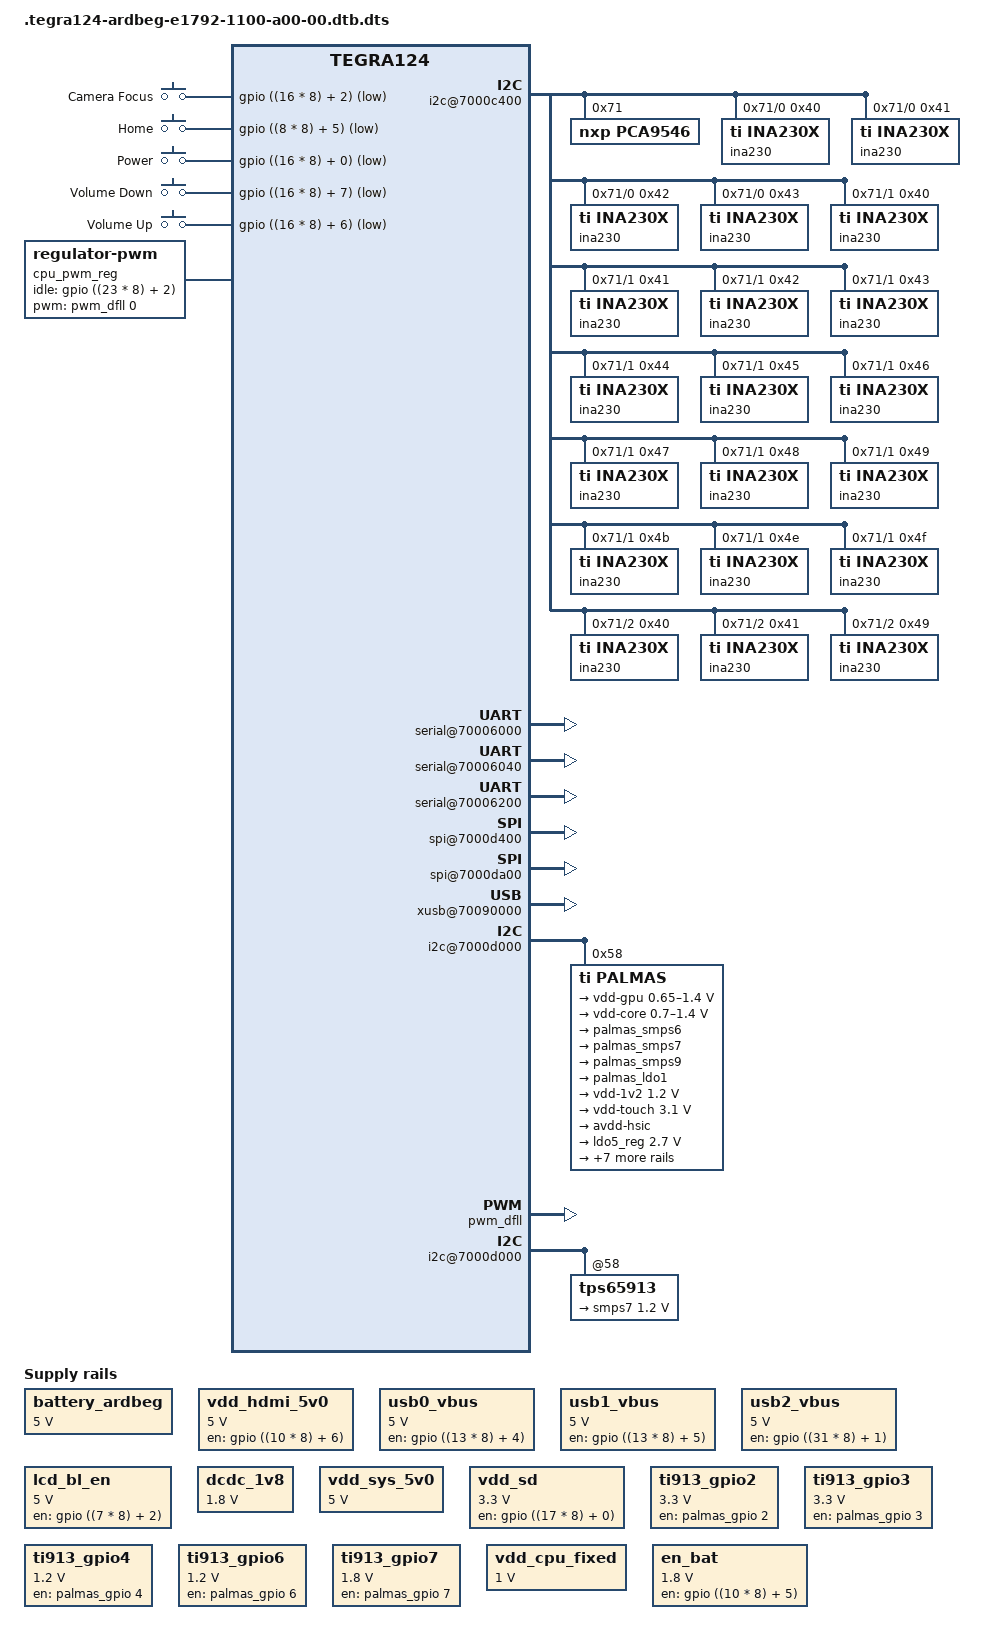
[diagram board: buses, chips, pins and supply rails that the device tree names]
# 1 "arch/arm/boot/dts/tegra124-ardbeg-e1792-1100-a00-00.dts"
# 1 "<built-in>"
# 1 "<command-line>"
# 1 "arch/arm/boot/dts/tegra124-ardbeg-e1792-1100-a00-00.dts"
/dts-v1/;

# 1 "arch/arm/boot/dts/tegra124-ardbeg-e1780-1000-a03-common.dtsi" 1




# 1 "arch/arm/boot/dts/tegra124.dtsi" 1
# 1 "/media/madman/Extended_Linux/21.8_l4t_build/kernel/arch/arm/boot/dts/include/dt-bindings/gpio/tegra-gpio.h" 1
# 13 "/media/madman/Extended_Linux/21.8_l4t_build/kernel/arch/arm/boot/dts/include/dt-bindings/gpio/tegra-gpio.h"
# 1 "/media/madman/Extended_Linux/21.8_l4t_build/kernel/arch/arm/boot/dts/include/dt-bindings/gpio/gpio.h" 1
# 14 "/media/madman/Extended_Linux/21.8_l4t_build/kernel/arch/arm/boot/dts/include/dt-bindings/gpio/tegra-gpio.h" 2
# 2 "arch/arm/boot/dts/tegra124.dtsi" 2
# 1 "/media/madman/Extended_Linux/21.8_l4t_build/kernel/arch/arm/boot/dts/include/dt-bindings/input/input.h" 1
# 3 "arch/arm/boot/dts/tegra124.dtsi" 2
# 1 "/media/madman/Extended_Linux/21.8_l4t_build/kernel/arch/arm/boot/dts/include/dt-bindings/interrupt-controller/arm-gic.h" 1







# 1 "/media/madman/Extended_Linux/21.8_l4t_build/kernel/arch/arm/boot/dts/include/dt-bindings/interrupt-controller/irq.h" 1
# 9 "/media/madman/Extended_Linux/21.8_l4t_build/kernel/arch/arm/boot/dts/include/dt-bindings/interrupt-controller/arm-gic.h" 2
# 4 "arch/arm/boot/dts/tegra124.dtsi" 2
# 1 "/media/madman/Extended_Linux/21.8_l4t_build/kernel/arch/arm/boot/dts/include/dt-bindings/ata/ahci-tegra.h" 1
# 5 "arch/arm/boot/dts/tegra124.dtsi" 2

/include/ "tegra124-soc.dtsi"

/ {
 compatible = "nvidia,tegra124";
 interrupt-parent = <&intc>;
 #address-cells = <2>;
 #size-cells = <2>;

 mc {
  compatible = "nvidia,tegra-mc";

  reg-ranges = <9>;
  reg = <0x0 0x70019000 0x0 0x00c>,
        <0x0 0x70019050 0x0 0x19c>,
        <0x0 0x70019200 0x0 0x024>,
        <0x0 0x7001929c 0x0 0x1b8>,
        <0x0 0x70019464 0x0 0x198>,
        <0x0 0x70019604 0x0 0x3b0>,
        <0x0 0x700199bc 0x0 0x020>,
        <0x0 0x700199f8 0x0 0x08c>,
        <0x0 0x70019ab4 0x0 0x54c>;

  interrupts = <0 77 0x4>;
  int_count = <8>;
  int_mask = <0x13D40>;

  channels = <1>;
 };

 intc: interrupt-controller@50041000 {
  compatible = "arm,cortex-a15-gic";
  interrupt-controller;
  #interrupt-cells = <3>;
  reg = <0x0 0x50041000 0x0 0x1000>,
        <0x0 0x50042000 0x0 0x0100>;
 };

 lic: interrupt-controller@60004000 {
  compatible = "nvidia,tegra-gic";
  interrupt-controller;
  reg = <0x0 0x60004000 0x0 0x40>,
        <0x0 0x60004100 0x0 0x40>,
        <0x0 0x60004200 0x0 0x40>,
        <0x0 0x60004300 0x0 0x40>,
        <0x0 0x60004400 0x0 0x40>;
        };

 cpus {
  #address-cells = <1>;
  #size-cells = <0>;

  cpu@0 {
   device_type = "cpu";
   compatible = "arm,cortex-a15";
   reg = <0>;
  };

  cpu@1 {
   device_type = "cpu";
   compatible = "arm,cortex-a15";
   reg = <1>;
  };

  cpu@2 {
   device_type = "cpu";
   compatible = "arm,cortex-a15";
   reg = <2>;
  };

  cpu@3 {
   device_type = "cpu";
   compatible = "arm,cortex-a15";
   reg = <3>;
  };
 };

 timer {
  compatible = "arm,armv7-timer";
  interrupts = <1 13 0xf04
         1 14 0xf04>;
 };

 dfll@70110000 {
   compatible = "nvidia,tegra124-dfll";
   reg = <0x0 0x70110000 0x0 0x400>;
   out-clock-name="dfll_cpu";
   status = "disabled";
 };
};
# 6 "arch/arm/boot/dts/tegra124-ardbeg-e1780-1000-a03-common.dtsi" 2
# 1 "arch/arm/boot/dts/tegra124-platforms/tegra124-ardbeg-powermon-e1780-1000-a01.dtsi" 1
# 18 "arch/arm/boot/dts/tegra124-platforms/tegra124-ardbeg-powermon-e1780-1000-a01.dtsi"
/ {
 i2c@7000c400 {
  pca9546@71 {
   compatible = "nxp,pca9546";
   reg = <0x71>;
   #address-cells = <1>;
   #size-cells = <0>;
   pca9546_i2c0: i2c@0 {
    reg = <0>;
    i2c-mux,deselect-on-exit;
    #address-cells = <1>;
    #size-cells = <0>;

    ina230@40{
     compatible = "ti,ina230x";
     reg = <0x40>;
     ti,rail-name = "__VDD_BAT";
     ti,continuous-config = <0x0407>;
     ti,trigger-config = <0x0403>;
     ti,resistor = <10>;
     ti,calibration-data = <0x1366>;
     ti,power-lsb = <2577>;
     ti,divisor = <25>;
     ti,precision-multiplier = <1000>;
    };

    ina230@41{
     compatible = "ti,ina230x";
     reg = <0x41>;
     ti,rail-name = "__VDD_SYS_BUCKCPU";
     ti,continuous-config = <0x0407>;
     ti,trigger-config = <0x0403>;
     ti,resistor = <10>;
     ti,calibration-data = <0x1AC5>;
     ti,power-lsb = <1867>;
     ti,divisor = <25>;
     ti,precision-multiplier = <1000>;
    };

    ina230@42{
     compatible = "ti,ina230x";
     reg = <0x42>;
     ti,rail-name = "__VDD_SYS_BUCKSOC";
     ti,continuous-config = <0x0407>;
     ti,trigger-config = <0x0403>;
     ti,resistor = <20>;
     ti,calibration-data = <0x2802>;
     ti,power-lsb = <624>;
     ti,divisor = <25>;
     ti,precision-multiplier = <1000>;
    };

    ina230@43{
     compatible = "ti,ina230x";
     reg = <0x43>;
     ti,rail-name = "__VDD_SYS_BUCKGPU";
     ti,continuous-config = <0x0407>;
     ti,trigger-config = <0x0403>;
     ti,resistor = <10>;
     ti,calibration-data = <0x1F38>;
     ti,power-lsb = <1601>;
     ti,divisor = <25>;
     ti,precision-multiplier = <1000>;
    };
   };

   pca9546_i2c1: i2c@1 {
    reg = <1>;
    i2c-mux,deselect-on-exit;
    #address-cells = <1>;
    #size-cells = <0>;
    ina230@40{
     compatible = "ti,ina230x";
     reg = <0x40>;
     ti,rail-name = "VDD_SYS_BAT";
     ti,continuous-config = <0x0407>;
     ti,trigger-config = <0x0403>;
     ti,resistor = <10>;
     ti,calibration-data = <0x1366>;
     ti,power-lsb = <2577>;
     ti,divisor = <25>;
     ti,precision-multiplier = <1000>;
    };

    ina230@41{
     compatible = "ti,ina230x";
     reg = <0x41>;
     ti,rail-name = "VDD_RTC_LDO3";
     ti,continuous-config = <0x0407>;
     ti,trigger-config = <0x0403>;
     ti,resistor = <50>;
     ti,calibration-data = <0x7FFF>;
     ti,power-lsb = <78>;
     ti,divisor = <25>;
     ti,precision-multiplier = <1000>;
    };

    ina230@42{
     compatible = "ti,ina230x";
     reg = <0x42>;
     ti,rail-name = "VDD_SYS_BUCKSOC";
     ti,continuous-config = <0x0407>;
     ti,trigger-config = <0x0403>;
     ti,resistor = <30>;
     ti,calibration-data = <0x1AAC>;
     ti,power-lsb = <624>;
     ti,divisor = <25>;
     ti,precision-multiplier = <1000>;
    };

    ina230@43{
     compatible = "ti,ina230x";
     reg = <0x43>;
     ti,rail-name = "VDD_SOC_SD1";
     ti,continuous-config = <0x0407>;
     ti,trigger-config = <0x0403>;
     ti,resistor = <1>;
     ti,calibration-data = <0x7FFF>;
     ti,power-lsb = <3906>;
     ti,divisor = <25>;
     ti,precision-multiplier = <1000>;
    };

    ina230@44{
     compatible = "ti,ina230x";
     reg = <0x44>;
     ti,rail-name = "VDD_SYS_BUCKCPU";
     ti,continuous-config = <0x0407>;
     ti,trigger-config = <0x0403>;
     ti,resistor = <10>;
     ti,calibration-data = <0x1AC5>;
     ti,power-lsb = <1867>;
     ti,divisor = <25>;
     ti,precision-multiplier = <1000>;
    };

    ina230@45{
     compatible = "ti,ina230x";
     reg = <0x45>;
     ti,rail-name = "VDD_CPU_BUCKCPU";
     ti,continuous-config = <0x0407>;
     ti,trigger-config = <0x0403>;
     ti,resistor = <1>;
     ti,calibration-data = <0x2ECF>;
     ti,power-lsb = <10681>;
     ti,divisor = <25>;
     ti,precision-multiplier = <1000>;
    };

    ina230@46{
     compatible = "ti,ina230x";
     reg = <0x46>;
     ti,rail-name = "VDD_1V8_SD5";
     ti,continuous-config = <0x0407>;
     ti,trigger-config = <0x0403>;
     ti,resistor = <10>;
     ti,calibration-data = <0x45F0>;
     ti,power-lsb = <714>;
     ti,divisor = <25>;
     ti,precision-multiplier = <1000>;
    };

    ina230@47{
     compatible = "ti,ina230x";
     reg = <0x47>;
     ti,rail-name = "VDD_3V3A_LDO1_6";
     ti,continuous-config = <0x0407>;
     ti,trigger-config = <0x0403>;
     ti,resistor = <200>;
     ti,calibration-data = <0x3A83>;
     ti,power-lsb = <42>;
     ti,divisor = <25>;
     ti,precision-multiplier = <1000>;
    };

    ina230@48{
     compatible = "ti,ina230x";
     reg = <0x48>;
     ti,rail-name = "VDD_DIS_3V3_LCD";
     ti,continuous-config = <0x0407>;
     ti,trigger-config = <0x0403>;
     ti,resistor = <10>;
     ti,calibration-data = <0x7FFF>;
     ti,power-lsb = <390>;
     ti,divisor = <25>;
     ti,precision-multiplier = <1000>;
    };

    ina230@49{
     compatible = "ti,ina230x";
     reg = <0x49>;
     ti,rail-name = "VDD_1V35_SD2";
     ti,continuous-config = <0x0407>;
     ti,trigger-config = <0x0403>;
     ti,resistor = <1>;
     ti,calibration-data = <0x7FFF>;
     ti,power-lsb = <3906>;
     ti,divisor = <25>;
     ti,precision-multiplier = <1000>;
    };

    ina230@4b{
     compatible = "ti,ina230x";
     reg = <0x4b>;
     ti,rail-name = "VDD_SYS_BUCKGPU";
     ti,continuous-config = <0x0407>;
     ti,trigger-config = <0x0403>;
     ti,resistor = <10>;
     ti,calibration-data = <0x1F38>;
     ti,power-lsb = <1601>;
     ti,divisor = <25>;
     ti,precision-multiplier = <1000>;
    };

    ina230@4e{
     compatible = "ti,ina230x";
     reg = <0x4e>;
     ti,rail-name = "VDD_LCD_1V8B_DIS";
     ti,continuous-config = <0x0407>;
     ti,trigger-config = <0x0403>;
     ti,resistor = <100>;
     ti,calibration-data = <0x7FFF>;
     ti,power-lsb = <39>;
     ti,divisor = <25>;
     ti,precision-multiplier = <1000>;
    };

    ina230@4f{
     compatible = "ti,ina230x";
     reg = <0x4f>;
     ti,rail-name = "VDD_1V05_LDO0";
     ti,continuous-config = <0x0407>;
     ti,trigger-config = <0x0403>;
     ti,resistor = <30>;
     ti,calibration-data = <0x7FFF>;
     ti,power-lsb = <130>;
     ti,divisor = <25>;
     ti,precision-multiplier = <1000>;
    };
   };

   pca9546_i2c2: i2c@2 {
    reg = <2>;
    i2c-mux,deselect-on-exit;
    #address-cells = <1>;
    #size-cells = <0>;
    ina230@40{
     compatible = "ti,ina230x";
     reg = <0x40>;
     ti,rail-name = "VDD_1V05_SD4";
     ti,continuous-config = <0x0407>;
     ti,trigger-config = <0x0403>;
     ti,resistor = <10>;
     ti,calibration-data = <0x7FFF>;
     ti,power-lsb = <390>;
     ti,divisor = <25>;
     ti,precision-multiplier = <1000>;
    };

    ina230@41{
     compatible = "ti,ina230x";
     reg = <0x41>;
     ti,rail-name = "VDD_1V8A_LDO2_5_7";
     ti,continuous-config = <0x0407>;
     ti,trigger-config = <0x0403>;
     ti,resistor = <20>;
     ti,calibration-data = <0x5A04>;
     ti,power-lsb = <277>;
     ti,divisor = <25>;
     ti,precision-multiplier = <1000>;
    };

    ina230@49{
     compatible = "ti,ina230x";
     reg = <0x49>;
     ti,rail-name = "VDD_SYS_BL";
     ti,continuous-config = <0x0407>;
     ti,trigger-config = <0x0403>;
     ti,resistor = <50>;
     ti,calibration-data = <0x2468>;
     ti,power-lsb = <274>;
     ti,divisor = <25>;
     ti,precision-multiplier = <1000>;
    };
   };

   pca9546_i2c3: i2c@3 {
    reg = <3>;
    i2c-mux,deselect-on-exit;
    #address-cells = <1>;
    #size-cells = <0>;
   };
  };
 };
};
# 7 "arch/arm/boot/dts/tegra124-ardbeg-e1780-1000-a03-common.dtsi" 2
# 1 "arch/arm/boot/dts/tegra124-platforms/tegra124-tn8-gpio-e1780-1100-a02.dtsi" 1
# 21 "arch/arm/boot/dts/tegra124-platforms/tegra124-tn8-gpio-e1780-1100-a02.dtsi"
/ {
 gpio: gpio@6000d000 {
  gpio-init-names = "default";
  gpio-init-0 = <&gpio_default>;

  gpio_default: default {
   gpio-input = < ((2 * 8) + 7)
     ((6 * 8) + 2)
     ((6 * 8) + 3)
     ((7 * 8) + 4)
     ((8 * 8) + 5)
     ((8 * 8) + 6)
     ((9 * 8) + 0)
     ((10 * 8) + 0)
     ((10 * 8) + 2)
     ((10 * 8) + 3)
     ((13 * 8) + 7)
     ((14 * 8) + 0)
     ((14 * 8) + 2)
     ((14 * 8) + 3)
     ((14 * 8) + 5)
     ((14 * 8) + 7)
     ((16 * 8) + 0)
     ((16 * 8) + 1)
     ((16 * 8) + 2)
     ((16 * 8) + 5)
     ((16 * 8) + 6)
     ((16 * 8) + 7)
     ((17 * 8) + 4)
     ((18 * 8) + 0)
     ((18 * 8) + 1)
     ((20 * 8) + 1)
     ((20 * 8) + 2)
     ((20 * 8) + 5)
     ((20 * 8) + 6)
     ((21 * 8) + 0)
     ((21 * 8) + 1)
     ((21 * 8) + 3)
     ((22 * 8) + 2)
     ((22 * 8) + 3)
     ((23 * 8) + 3)
     ((23 * 8) + 5)
     ((23 * 8) + 6)
     ((28 * 8) + 1)
     ((28 * 8) + 2)>;
   gpio-output-low = <((6 * 8) + 0)
     ((6 * 8) + 1)
     ((7 * 8) + 3)
     ((7 * 8) + 5)
     ((8 * 8) + 0)
     ((8 * 8) + 2)
     ((8 * 8) + 4)
     ((10 * 8) + 1)
     ((10 * 8) + 5)
     ((10 * 8) + 6)
     ((14 * 8) + 6)
     ((17 * 8) + 0)
     ((17 * 8) + 1)
     ((17 * 8) + 2)
     ((17 * 8) + 5)
     ((18 * 8) + 3)
     ((18 * 8) + 4)
     ((18 * 8) + 6)
     ((20 * 8) + 0)
     ((20 * 8) + 3)
     ((20 * 8) + 4)
     ((23 * 8) + 1)
     ((23 * 8) + 4)
     ((23 * 8) + 7)
     ((27 * 8) + 3)
     ((27 * 8) + 5)
     ((27 * 8) + 6)
     ((27 * 8) + 7)
     ((28 * 8) + 5)
     ((30 * 8) + 1)>;
   gpio-output-high = <((7 * 8) + 2)
     ((10 * 8) + 4)
     ((18 * 8) + 5)
     ((23 * 8) + 2)>;
  };
 };
};
# 8 "arch/arm/boot/dts/tegra124-ardbeg-e1780-1000-a03-common.dtsi" 2
# 1 "arch/arm/boot/dts/tegra124-platforms/tegra124-tn8-pinmux-e1780-1100-a02.dtsi" 1
# 19 "arch/arm/boot/dts/tegra124-platforms/tegra124-tn8-pinmux-e1780-1100-a02.dtsi"
# 1 "/media/madman/Extended_Linux/21.8_l4t_build/kernel/arch/arm/boot/dts/include/dt-bindings/pinctrl/pinctrl-tegra.h" 1
# 20 "arch/arm/boot/dts/tegra124-platforms/tegra124-tn8-pinmux-e1780-1100-a02.dtsi" 2

/ {

 i2c@7000c000 {
                pinctrl-names = "hs_mode";
                pinctrl-0 = <&gen1_i2c_hs_drive>;
        };

 i2c@7000c400 {
                pinctrl-names = "hs_mode";
                pinctrl-0 = <&gen2_i2c_hs_drive>;
        };

 i2c@7000c500 {
                pinctrl-names = "hs_mode";
                pinctrl-0 = <&cam_i2c_hs_drive>;
        };

 i2c@7000c700 {
                pinctrl-names = "hs_mode";
                pinctrl-0 = <&ddc_i2c_hs_drive>;
        };

 i2c@7000d000 {
                pinctrl-names = "hs_mode";
                pinctrl-0 = <&pwr_i2c_hs_drive>;
        };

 pinmux: pinmux {
  pinctrl-names = "default", "drive", "unused", "gen1_i2c_hs", "gen2_i2c_hs", "cam_i2c_hs", "ddc_i2c_hs", "pwr_i2c_hs";
  pinctrl-0 = <&pinmux_default>;
  pinctrl-1 = <&drive_default>;
  pinctrl-2 = <&pinmux_unused_lowpower>;
  pinctrl-3 = <&gen1_i2c_hs_drive>;
  pinctrl-4 = <&gen2_i2c_hs_drive>;
  pinctrl-5 = <&cam_i2c_hs_drive>;
  pinctrl-6 = <&ddc_i2c_hs_drive>;
  pinctrl-7 = <&pwr_i2c_hs_drive>;

  pinmux_default: common {
   dap_mclk1_pw4 {
    nvidia,pins = "dap_mclk1_pw4";
    nvidia,function = "extperiph1";
    nvidia,enable-input = <0>;
    nvidia,pull = <0>;
    nvidia,tristate = <0>;
   };

   dap1_din_pn1 {
    nvidia,pins = "dap1_din_pn1";
    nvidia,function = "i2s0";
    nvidia,enable-input = <1>;
    nvidia,pull = <0>;
    nvidia,tristate = <1>;
   };

   dap1_dout_pn2 {
    nvidia,pins = "dap1_dout_pn2";
    nvidia,function = "i2s0";
    nvidia,enable-input = <0>;
    nvidia,pull = <0>;
    nvidia,tristate = <1>;
   };

   dap1_fs_pn0 {
    nvidia,pins = "dap1_fs_pn0";
    nvidia,function = "i2s0";
    nvidia,enable-input = <1>;
    nvidia,pull = <0>;
    nvidia,tristate = <1>;
   };

   dap1_sclk_pn3 {
    nvidia,pins = "dap1_sclk_pn3";
    nvidia,function = "i2s0";
    nvidia,enable-input = <1>;
    nvidia,pull = <0>;
    nvidia,tristate = <1>;
   };

   dap2_din_pa4 {
    nvidia,pins = "dap2_din_pa4";
    nvidia,function = "i2s1";
    nvidia,enable-input = <1>;
    nvidia,pull = <0>;
    nvidia,tristate = <1>;
   };

   dap2_dout_pa5 {
    nvidia,pins = "dap2_dout_pa5";
    nvidia,function = "i2s1";
    nvidia,enable-input = <0>;
    nvidia,pull = <0>;
    nvidia,tristate = <1>;
   };

   dap2_fs_pa2 {
    nvidia,pins = "dap2_fs_pa2";
    nvidia,function = "i2s1";
    nvidia,enable-input = <1>;
    nvidia,pull = <0>;
    nvidia,tristate = <1>;
   };

   dap2_sclk_pa3 {
    nvidia,pins = "dap2_sclk_pa3";
    nvidia,function = "i2s1";
    nvidia,enable-input = <1>;
    nvidia,pull = <0>;
    nvidia,tristate = <1>;
   };

   dvfs_pwm_px0 {
    nvidia,pins = "dvfs_pwm_px0";
    nvidia,function = "cldvfs";
    nvidia,enable-input = <0>;
    nvidia,pull = <0>;
    nvidia,tristate = <1>;
   };

   dvfs_clk_px2 {
    nvidia,pins = "dvfs_clk_px2";
    nvidia,function = "cldvfs";
    nvidia,enable-input = <0>;
    nvidia,pull = <0>;
    nvidia,tristate = <0>;
   };

   ulpi_clk_py0 {
    nvidia,pins = "ulpi_clk_py0";
    nvidia,function = "spi1";
    nvidia,enable-input = <1>;
    nvidia,pull = <2>;
    nvidia,tristate = <0>;
   };

   ulpi_dir_py1 {
    nvidia,pins = "ulpi_dir_py1";
    nvidia,function = "spi1";
    nvidia,enable-input = <1>;
    nvidia,pull = <2>;
    nvidia,tristate = <0>;
   };

   ulpi_nxt_py2 {
    nvidia,pins = "ulpi_nxt_py2";
    nvidia,function = "spi1";
    nvidia,enable-input = <1>;
    nvidia,pull = <2>;
    nvidia,tristate = <0>;
   };

   ulpi_stp_py3 {
    nvidia,pins = "ulpi_stp_py3";
    nvidia,function = "spi1";
    nvidia,enable-input = <1>;
    nvidia,pull = <2>;
    nvidia,tristate = <0>;
   };

   cam_i2c_scl_pbb1 {
    nvidia,pins = "cam_i2c_scl_pbb1";
    nvidia,function = "i2c3";
    nvidia,enable-input = <1>;
    nvidia,pull = <0>;
    nvidia,tristate = <0>;
    nvidia,lock = <0>;
    nvidia,open-drain = <1>;
   };

   cam_i2c_sda_pbb2 {
    nvidia,pins = "cam_i2c_sda_pbb2";
    nvidia,function = "i2c3";
    nvidia,enable-input = <1>;
    nvidia,pull = <0>;
    nvidia,tristate = <0>;
    nvidia,lock = <0>;
    nvidia,open-drain = <1>;
   };

   cam_mclk_pcc0 {
    nvidia,pins = "cam_mclk_pcc0";
    nvidia,function = "vi_alt3";
    nvidia,enable-input = <0>;
    nvidia,pull = <0>;
    nvidia,tristate = <0>;
   };

   pbb0 {
    nvidia,pins = "pbb0";
    nvidia,function = "vimclk2_alt";
    nvidia,enable-input = <0>;
    nvidia,pull = <0>;
    nvidia,tristate = <0>;
   };

   pbb4 {
    nvidia,pins = "pbb4";
    nvidia,function = "vgp4";
    nvidia,enable-input = <0>;
    nvidia,pull = <0>;
    nvidia,tristate = <0>;
   };

   gen2_i2c_scl_pt5 {
    nvidia,pins = "gen2_i2c_scl_pt5";
    nvidia,function = "i2c2";
    nvidia,enable-input = <1>;
    nvidia,pull = <0>;
    nvidia,tristate = <0>;
    nvidia,lock = <0>;
    nvidia,open-drain = <1>;
   };

   gen2_i2c_sda_pt6 {
    nvidia,pins = "gen2_i2c_sda_pt6";
    nvidia,function = "i2c2";
    nvidia,enable-input = <1>;
    nvidia,pull = <0>;
    nvidia,tristate = <0>;
    nvidia,lock = <0>;
    nvidia,open-drain = <1>;
   };

   pj7 {
    nvidia,pins = "pj7";
    nvidia,function = "uartd";
    nvidia,enable-input = <0>;
    nvidia,pull = <0>;
    nvidia,tristate = <0>;
   };

   pb0 {
    nvidia,pins = "pb0";
    nvidia,function = "uartd";
    nvidia,enable-input = <1>;
    nvidia,pull = <2>;
    nvidia,tristate = <0>;
   };

   pb1 {
    nvidia,pins = "pb1";
    nvidia,function = "uartd";
    nvidia,enable-input = <1>;
    nvidia,pull = <2>;
    nvidia,tristate = <0>;
   };

   pk7 {
    nvidia,pins = "pk7";
    nvidia,function = "uartd";
    nvidia,enable-input = <0>;
    nvidia,pull = <0>;
    nvidia,tristate = <0>;
   };

   pg4 {
    nvidia,pins = "pg4";
    nvidia,function = "spi4";
    nvidia,enable-input = <0>;
    nvidia,pull = <0>;
    nvidia,tristate = <0>;
   };

   pg5 {
    nvidia,pins = "pg5";
    nvidia,function = "spi4";
    nvidia,enable-input = <0>;
    nvidia,pull = <0>;
    nvidia,tristate = <0>;
   };

   pg6 {
    nvidia,pins = "pg6";
    nvidia,function = "spi4";
    nvidia,enable-input = <0>;
    nvidia,pull = <0>;
    nvidia,tristate = <0>;
   };

   pg7 {
    nvidia,pins = "pg7";
    nvidia,function = "spi4";
    nvidia,enable-input = <1>;
    nvidia,pull = <0>;
    nvidia,tristate = <0>;
   };

   pi3 {
    nvidia,pins = "pi3";
    nvidia,function = "spi4";
    nvidia,enable-input = <0>;
    nvidia,pull = <0>;
    nvidia,tristate = <0>;
   };

   ph0 {
    nvidia,pins = "ph0";
    nvidia,function = "dtv";
    nvidia,enable-input = <1>;
    nvidia,pull = <1>;
    nvidia,tristate = <1>;
   };

   ph1 {
    nvidia,pins = "ph1";
    nvidia,function = "pwm1";
    nvidia,enable-input = <0>;
    nvidia,pull = <0>;
    nvidia,tristate = <0>;
   };

   pk0 {
    nvidia,pins = "pk0";
    nvidia,function = "safe";
    nvidia,enable-input = <1>;
    nvidia,pull = <1>;
    nvidia,tristate = <0>;
   };

   pj2 {
    nvidia,pins = "pj2";
    nvidia,function = "soc";
    nvidia,enable-input = <1>;
    nvidia,pull = <2>;
    nvidia,tristate = <0>;
   };

   kb_row15_ps7 {
    nvidia,pins = "kb_row15_ps7";
    nvidia,function = "soc";
    nvidia,enable-input = <1>;
    nvidia,pull = <2>;
    nvidia,tristate = <0>;
   };

   clk_32k_out_pa0 {
    nvidia,pins = "clk_32k_out_pa0";
    nvidia,function = "soc";
    nvidia,enable-input = <1>;
    nvidia,pull = <2>;
    nvidia,tristate = <0>;
   };

   clk2_out_pw5 {
    nvidia,pins = "clk2_out_pw5";
    nvidia,function = "extperiph2";
    nvidia,enable-input = <0>;
    nvidia,pull = <0>;
    nvidia,tristate = <0>;
   };

   sdmmc1_clk_pz0 {
    nvidia,pins = "sdmmc1_clk_pz0";
    nvidia,function = "sdmmc1";
    nvidia,enable-input = <1>;
    nvidia,pull = <0>;
    nvidia,tristate = <0>;
   };

   sdmmc1_cmd_pz1 {
    nvidia,pins = "sdmmc1_cmd_pz1";
    nvidia,function = "sdmmc1";
    nvidia,enable-input = <1>;
    nvidia,pull = <2>;
    nvidia,tristate = <0>;
   };

   sdmmc1_dat0_py7 {
    nvidia,pins = "sdmmc1_dat0_py7";
    nvidia,function = "sdmmc1";
    nvidia,enable-input = <1>;
    nvidia,pull = <2>;
    nvidia,tristate = <0>;
   };

   sdmmc1_dat1_py6 {
    nvidia,pins = "sdmmc1_dat1_py6";
    nvidia,function = "sdmmc1";
    nvidia,enable-input = <1>;
    nvidia,pull = <2>;
    nvidia,tristate = <0>;
   };

   sdmmc1_dat2_py5 {
    nvidia,pins = "sdmmc1_dat2_py5";
    nvidia,function = "sdmmc1";
    nvidia,enable-input = <1>;
    nvidia,pull = <2>;
    nvidia,tristate = <0>;
   };

   sdmmc1_dat3_py4 {
    nvidia,pins = "sdmmc1_dat3_py4";
    nvidia,function = "sdmmc1";
    nvidia,enable-input = <1>;
    nvidia,pull = <2>;
    nvidia,tristate = <0>;
   };

   sdmmc3_clk_pa6 {
    nvidia,pins = "sdmmc3_clk_pa6";
    nvidia,function = "sdmmc3";
    nvidia,enable-input = <1>;
    nvidia,pull = <0>;
    nvidia,tristate = <0>;
   };

   sdmmc3_cmd_pa7 {
    nvidia,pins = "sdmmc3_cmd_pa7";
    nvidia,function = "sdmmc3";
    nvidia,enable-input = <1>;
    nvidia,pull = <2>;
    nvidia,tristate = <0>;
   };

   sdmmc3_dat0_pb7 {
    nvidia,pins = "sdmmc3_dat0_pb7";
    nvidia,function = "sdmmc3";
    nvidia,enable-input = <1>;
    nvidia,pull = <2>;
    nvidia,tristate = <0>;
   };

   sdmmc3_dat1_pb6 {
    nvidia,pins = "sdmmc3_dat1_pb6";
    nvidia,function = "sdmmc3";
    nvidia,enable-input = <1>;
    nvidia,pull = <2>;
    nvidia,tristate = <0>;
   };

   sdmmc3_dat2_pb5 {
    nvidia,pins = "sdmmc3_dat2_pb5";
    nvidia,function = "sdmmc3";
    nvidia,enable-input = <1>;
    nvidia,pull = <2>;
    nvidia,tristate = <0>;
   };

   sdmmc3_dat3_pb4 {
    nvidia,pins = "sdmmc3_dat3_pb4";
    nvidia,function = "sdmmc3";
    nvidia,enable-input = <1>;
    nvidia,pull = <2>;
    nvidia,tristate = <0>;
   };

   sdmmc3_clk_lb_out_pee4 {
    nvidia,pins = "sdmmc3_clk_lb_out_pee4";
    nvidia,function = "sdmmc3";
    nvidia,enable-input = <1>;
    nvidia,pull = <2>;
    nvidia,tristate = <0>;
   };

   sdmmc3_clk_lb_in_pee5 {
    nvidia,pins = "sdmmc3_clk_lb_in_pee5";
    nvidia,function = "sdmmc3";
    nvidia,enable-input = <1>;
    nvidia,pull = <2>;
    nvidia,tristate = <0>;
   };

   kb_col4_pq4 {
    nvidia,pins = "kb_col4_pq4";
    nvidia,function = "sdmmc3";
    nvidia,enable-input = <1>;
    nvidia,pull = <2>;
    nvidia,tristate = <0>;
   };

   sdmmc3_cd_n_pv2 {
    nvidia,pins = "sdmmc3_cd_n_pv2";
    nvidia,function = "sdmmc3";
    nvidia,enable-input = <1>;
    nvidia,pull = <2>;
    nvidia,tristate = <0>;
   };

   sdmmc4_clk_pcc4 {
    nvidia,pins = "sdmmc4_clk_pcc4";
    nvidia,function = "sdmmc4";
    nvidia,enable-input = <1>;
    nvidia,pull = <0>;
    nvidia,tristate = <0>;
   };

   sdmmc4_cmd_pt7 {
    nvidia,pins = "sdmmc4_cmd_pt7";
    nvidia,function = "sdmmc4";
    nvidia,enable-input = <1>;
    nvidia,pull = <2>;
    nvidia,tristate = <0>;
   };

   sdmmc4_dat0_paa0 {
    nvidia,pins = "sdmmc4_dat0_paa0";
    nvidia,function = "sdmmc4";
    nvidia,enable-input = <1>;
    nvidia,pull = <2>;
    nvidia,tristate = <0>;
   };

   sdmmc4_dat1_paa1 {
    nvidia,pins = "sdmmc4_dat1_paa1";
    nvidia,function = "sdmmc4";
    nvidia,enable-input = <1>;
    nvidia,pull = <2>;
    nvidia,tristate = <0>;
   };

   sdmmc4_dat2_paa2 {
    nvidia,pins = "sdmmc4_dat2_paa2";
    nvidia,function = "sdmmc4";
    nvidia,enable-input = <1>;
    nvidia,pull = <2>;
    nvidia,tristate = <0>;
   };

   sdmmc4_dat3_paa3 {
    nvidia,pins = "sdmmc4_dat3_paa3";
    nvidia,function = "sdmmc4";
    nvidia,enable-input = <1>;
    nvidia,pull = <2>;
    nvidia,tristate = <0>;
   };

   sdmmc4_dat4_paa4 {
    nvidia,pins = "sdmmc4_dat4_paa4";
    nvidia,function = "sdmmc4";
    nvidia,enable-input = <1>;
    nvidia,pull = <2>;
    nvidia,tristate = <0>;
   };

   sdmmc4_dat5_paa5 {
    nvidia,pins = "sdmmc4_dat5_paa5";
    nvidia,function = "sdmmc4";
    nvidia,enable-input = <1>;
    nvidia,pull = <2>;
    nvidia,tristate = <0>;
   };

   sdmmc4_dat6_paa6 {
    nvidia,pins = "sdmmc4_dat6_paa6";
    nvidia,function = "sdmmc4";
    nvidia,enable-input = <1>;
    nvidia,pull = <2>;
    nvidia,tristate = <0>;
   };

   sdmmc4_dat7_paa7 {
    nvidia,pins = "sdmmc4_dat7_paa7";
    nvidia,function = "sdmmc4";
    nvidia,enable-input = <1>;
    nvidia,pull = <2>;
    nvidia,tristate = <0>;
   };

   kb_row10_ps2 {
    nvidia,pins = "kb_row10_ps2";
    nvidia,function = "uarta";
    nvidia,enable-input = <1>;
    nvidia,pull = <2>;
    nvidia,tristate = <0>;
   };

   kb_row9_ps1 {
    nvidia,pins = "kb_row9_ps1";
    nvidia,function = "uarta";
    nvidia,enable-input = <0>;
    nvidia,pull = <0>;
    nvidia,tristate = <0>;
   };

   kb_row3_pr3 {
    nvidia,pins = "kb_row3_pr3";
    nvidia,function = "sys";
    nvidia,enable-input = <0>;
    nvidia,pull = <0>;
    nvidia,tristate = <0>;
   };

   kb_row6_pr6 {
    nvidia,pins = "kb_row6_pr6";
    nvidia,function = "displaya_alt";
    nvidia,enable-input = <1>;
    nvidia,pull = <0>;
    nvidia,tristate = <0>;
   };

   pwr_i2c_scl_pz6 {
    nvidia,pins = "pwr_i2c_scl_pz6";
    nvidia,function = "i2cpwr";
    nvidia,enable-input = <1>;
    nvidia,pull = <0>;
    nvidia,tristate = <0>;
    nvidia,open-drain = <1>;
   };

   pwr_i2c_sda_pz7 {
    nvidia,pins = "pwr_i2c_sda_pz7";
    nvidia,function = "i2cpwr";
    nvidia,enable-input = <1>;
    nvidia,pull = <0>;
    nvidia,tristate = <0>;
    nvidia,open-drain = <1>;
   };

   jtag_rtck {
    nvidia,pins = "jtag_rtck";
    nvidia,function = "rtck";
    nvidia,enable-input = <0>;
    nvidia,pull = <2>;
    nvidia,tristate = <0>;
   };

   clk_32k_in {
    nvidia,pins = "clk_32k_in";
    nvidia,function = "clk";
    nvidia,enable-input = <1>;
    nvidia,pull = <0>;
    nvidia,tristate = <0>;
   };

   core_pwr_req {
    nvidia,pins = "core_pwr_req";
    nvidia,function = "pwron";
    nvidia,enable-input = <0>;
    nvidia,pull = <0>;
    nvidia,tristate = <0>;
   };

   cpu_pwr_req {
    nvidia,pins = "cpu_pwr_req";
    nvidia,function = "cpu";
    nvidia,enable-input = <0>;
    nvidia,pull = <0>;
    nvidia,tristate = <0>;
   };

   pwr_int_n {
    nvidia,pins = "pwr_int_n";
    nvidia,function = "pmi";
    nvidia,enable-input = <1>;
    nvidia,pull = <2>;
    nvidia,tristate = <0>;
   };

   reset_out_n {
    nvidia,pins = "reset_out_n";
    nvidia,function = "reset_out_n";
    nvidia,enable-input = <0>;
    nvidia,pull = <0>;
    nvidia,tristate = <0>;
   };

   clk3_out_pee0 {
    nvidia,pins = "clk3_out_pee0";
    nvidia,function = "extperiph3";
    nvidia,enable-input = <0>;
    nvidia,pull = <0>;
    nvidia,tristate = <0>;
   };

   dp_hpd_pff0 {
    nvidia,pins = "dp_hpd_pff0";
    nvidia,function = "dp";
    nvidia,enable-input = <1>;
    nvidia,pull = <0>;
    nvidia,tristate = <0>;
   };

   dap4_din_pp5 {
    nvidia,pins = "dap4_din_pp5";
    nvidia,function = "i2s3";
    nvidia,enable-input = <1>;
    nvidia,pull = <0>;
    nvidia,tristate = <1>;
   };

   dap4_dout_pp6 {
    nvidia,pins = "dap4_dout_pp6";
    nvidia,function = "i2s3";
    nvidia,enable-input = <0>;
    nvidia,pull = <0>;
    nvidia,tristate = <1>;
   };

   dap4_fs_pp4 {
    nvidia,pins = "dap4_fs_pp4";
    nvidia,function = "i2s3";
    nvidia,enable-input = <1>;
    nvidia,pull = <0>;
    nvidia,tristate = <1>;
   };

   dap4_sclk_pp7 {
    nvidia,pins = "dap4_sclk_pp7";
    nvidia,function = "i2s3";
    nvidia,enable-input = <1>;
    nvidia,pull = <0>;
    nvidia,tristate = <1>;
   };

   gen1_i2c_sda_pc5 {
    nvidia,pins = "gen1_i2c_sda_pc5";
    nvidia,function = "i2c1";
    nvidia,enable-input = <1>;
    nvidia,pull = <0>;
    nvidia,tristate = <0>;
    nvidia,lock = <0>;
    nvidia,open-drain = <0>;
   };

   gen1_i2c_scl_pc4 {
    nvidia,pins = "gen1_i2c_scl_pc4";
    nvidia,function = "i2c1";
    nvidia,enable-input = <1>;
    nvidia,pull = <0>;
    nvidia,tristate = <0>;
    nvidia,lock = <0>;
    nvidia,open-drain = <0>;
   };

   uart2_cts_n_pj5 {
    nvidia,pins = "uart2_cts_n_pj5";
    nvidia,function = "uartb";
    nvidia,enable-input = <1>;
    nvidia,pull = <2>;
    nvidia,tristate = <0>;
   };

   uart2_rts_n_pj6 {
    nvidia,pins = "uart2_rts_n_pj6";
    nvidia,function = "uartb";
    nvidia,enable-input = <0>;
    nvidia,pull = <2>;
    nvidia,tristate = <0>;
   };

   uart2_rxd_pc3 {
    nvidia,pins = "uart2_rxd_pc3";
    nvidia,function = "irda";
    nvidia,enable-input = <1>;
    nvidia,pull = <2>;
    nvidia,tristate = <0>;
   };

   uart2_txd_pc2 {
    nvidia,pins = "uart2_txd_pc2";
    nvidia,function = "irda";
    nvidia,enable-input = <0>;
    nvidia,pull = <2>;
    nvidia,tristate = <0>;
   };

   uart3_cts_n_pa1 {
    nvidia,pins = "uart3_cts_n_pa1";
    nvidia,function = "uartc";
    nvidia,enable-input = <1>;
    nvidia,pull = <2>;
    nvidia,tristate = <0>;
   };

   uart3_rts_n_pc0 {
    nvidia,pins = "uart3_rts_n_pc0";
    nvidia,function = "uartc";
    nvidia,enable-input = <0>;
    nvidia,pull = <2>;
    nvidia,tristate = <0>;
   };

   uart3_rxd_pw7 {
    nvidia,pins = "uart3_rxd_pw7";
    nvidia,function = "uartc";
    nvidia,enable-input = <1>;
    nvidia,pull = <2>;
    nvidia,tristate = <0>;
   };

   uart3_txd_pw6 {
    nvidia,pins = "uart3_txd_pw6";
    nvidia,function = "uartc";
    nvidia,enable-input = <0>;
    nvidia,pull = <2>;
    nvidia,tristate = <0>;
   };

   hdmi_cec_pee3 {
    nvidia,pins = "hdmi_cec_pee3";
    nvidia,function = "cec";
    nvidia,enable-input = <1>;
    nvidia,pull = <0>;
    nvidia,tristate = <0>;
    nvidia,open-drain = <1>;
   };

   ddc_scl_pv4 {
    nvidia,pins = "ddc_scl_pv4";
    nvidia,function = "i2c4";
    nvidia,enable-input = <1>;
    nvidia,pull = <0>;
    nvidia,tristate = <0>;
   };

   ddc_sda_pv5 {
    nvidia,pins = "ddc_sda_pv5";
    nvidia,function = "i2c4";
    nvidia,enable-input = <1>;
    nvidia,pull = <0>;
    nvidia,tristate = <0>;
   };

   usb_vbus_en0_pn4 {
    nvidia,pins = "usb_vbus_en0_pn4";
    nvidia,function = "usb";
    nvidia,enable-input = <1>;
    nvidia,pull = <2>;
    nvidia,tristate = <0>;
    nvidia,lock = <0>;
    nvidia,open-drain = <0>;
   };

   usb_vbus_en1_pn5 {
    nvidia,pins = "usb_vbus_en1_pn5";
    nvidia,function = "usb";
    nvidia,enable-input = <1>;
    nvidia,pull = <2>;
    nvidia,tristate = <0>;
    nvidia,lock = <0>;
    nvidia,open-drain = <0>;
   };

   usb_vbus_en2_pff1 {
    nvidia,pins = "usb_vbus_en2_pff1";
    nvidia,function = "usb";
    nvidia,enable-input = <1>;
    nvidia,pull = <2>;
    nvidia,tristate = <0>;
    nvidia,lock = <0>;
    nvidia,open-drain = <0>;
   };

   ph6 {
    nvidia,pins = "ph6";
    nvidia,function = "dtv";
    nvidia,enable-input = <1>;
    nvidia,pull = <1>;
    nvidia,tristate = <1>;
   };

   ph7 {
    nvidia,pins = "ph7";
    nvidia,function = "dtv";
    nvidia,enable-input = <1>;
    nvidia,pull = <1>;
    nvidia,tristate = <1>;
   };

   pi7 {
    nvidia,pins = "pi7";
    nvidia,function = "dtv";
    nvidia,enable-input = <1>;
    nvidia,pull = <1>;
    nvidia,tristate = <1>;
   };

   gpio_x4_aud_px4 {
    nvidia,pins = "gpio_x4_aud_px4";
    nvidia,function = "safe";
    nvidia,enable-input = <0>;
    nvidia,pull = <0>;
    nvidia,tristate = <0>;
   };

   gpio_x5_aud_px5 {
    nvidia,pins = "gpio_x5_aud_px5";
    nvidia,function = "safe";
    nvidia,enable-input = <1>;
    nvidia,pull = <2>;
    nvidia,tristate = <0>;
   };

   gpio_x6_aud_px6 {
    nvidia,pins = "gpio_x6_aud_px6";
    nvidia,function = "safe";
    nvidia,enable-input = <1>;
    nvidia,pull = <2>;
    nvidia,tristate = <0>;
   };

   gpio_x7_aud_px7 {
    nvidia,pins = "gpio_x7_aud_px7";
    nvidia,function = "safe";
    nvidia,enable-input = <0>;
    nvidia,pull = <0>;
    nvidia,tristate = <0>;
   };

   gpio_w2_aud_pw2 {
    nvidia,pins = "gpio_w2_aud_pw2";
    nvidia,function = "safe";
    nvidia,enable-input = <1>;
    nvidia,pull = <2>;
    nvidia,tristate = <0>;
   };

   gpio_w3_aud_pw3 {
    nvidia,pins = "gpio_w3_aud_pw3";
    nvidia,function = "safe";
    nvidia,enable-input = <1>;
    nvidia,pull = <2>;
    nvidia,tristate = <0>;
   };

   gpio_x1_aud_px1 {
    nvidia,pins = "gpio_x1_aud_px1";
    nvidia,function = "safe";
    nvidia,enable-input = <0>;
    nvidia,pull = <0>;
    nvidia,tristate = <0>;
   };

   gpio_x3_aud_px3 {
    nvidia,pins = "gpio_x3_aud_px3";
    nvidia,function = "safe";
    nvidia,enable-input = <1>;
    nvidia,pull = <2>;
    nvidia,tristate = <0>;
   };

   pv0 {
    nvidia,pins = "pv0";
    nvidia,function = "safe";
    nvidia,enable-input = <1>;
    nvidia,pull = <2>;
    nvidia,tristate = <0>;
   };

   pv1 {
    nvidia,pins = "pv1";
    nvidia,function = "safe";
    nvidia,enable-input = <1>;
    nvidia,pull = <2>;
    nvidia,tristate = <0>;
   };

   ulpi_data1_po2 {
    nvidia,pins = "ulpi_data1_po2";
    nvidia,function = "safe";
    nvidia,enable-input = <1>;
    nvidia,pull = <2>;
    nvidia,tristate = <0>;
   };

   ulpi_data2_po3 {
    nvidia,pins = "ulpi_data2_po3";
    nvidia,function = "safe";
    nvidia,enable-input = <1>;
    nvidia,pull = <2>;
    nvidia,tristate = <0>;
   };

   ulpi_data4_po5 {
    nvidia,pins = "ulpi_data4_po5";
    nvidia,function = "safe";
    nvidia,enable-input = <1>;
    nvidia,pull = <2>;
    nvidia,tristate = <0>;
   };

   ulpi_data5_po6 {
    nvidia,pins = "ulpi_data5_po6";
    nvidia,function = "safe";
    nvidia,enable-input = <0>;
    nvidia,pull = <0>;
    nvidia,tristate = <0>;
   };

   ulpi_data6_po7 {
    nvidia,pins = "ulpi_data6_po7";
    nvidia,function = "safe";
    nvidia,enable-input = <1>;
    nvidia,pull = <2>;
    nvidia,tristate = <0>;
   };

   ulpi_data7_po0 {
    nvidia,pins = "ulpi_data7_po0";
    nvidia,function = "safe";
    nvidia,enable-input = <1>;
    nvidia,pull = <2>;
    nvidia,tristate = <0>;
   };

   pbb3 {
    nvidia,pins = "pbb3";
    nvidia,function = "safe";
    nvidia,enable-input = <0>;
    nvidia,pull = <0>;
    nvidia,tristate = <0>;
   };

   pbb5 {
    nvidia,pins = "pbb5";
    nvidia,function = "safe";
    nvidia,enable-input = <0>;
    nvidia,pull = <0>;
    nvidia,tristate = <0>;
   };

   pbb6 {
    nvidia,pins = "pbb6";
    nvidia,function = "safe";
    nvidia,enable-input = <0>;
    nvidia,pull = <0>;
    nvidia,tristate = <0>;
   };

   pbb7 {
    nvidia,pins = "pbb7";
    nvidia,function = "safe";
    nvidia,enable-input = <0>;
    nvidia,pull = <0>;
    nvidia,tristate = <0>;
   };

   pcc1 {
    nvidia,pins = "pcc1";
    nvidia,function = "safe";
    nvidia,enable-input = <1>;
    nvidia,pull = <1>;
    nvidia,tristate = <0>;
   };

   pcc2 {
    nvidia,pins = "pcc2";
    nvidia,function = "safe";
    nvidia,enable-input = <1>;
    nvidia,pull = <1>;
    nvidia,tristate = <0>;
   };

   pg0 {
    nvidia,pins = "pg0";
    nvidia,function = "safe";
    nvidia,enable-input = <0>;
    nvidia,pull = <0>;
    nvidia,tristate = <0>;
   };

   pg1 {
    nvidia,pins = "pg1";
    nvidia,function = "safe";
    nvidia,enable-input = <0>;
    nvidia,pull = <0>;
    nvidia,tristate = <0>;
   };

   ph2 {
    nvidia,pins = "ph2";
    nvidia,function = "safe";
    nvidia,enable-input = <0>;
    nvidia,pull = <0>;
    nvidia,tristate = <0>;
   };

   ph3 {
    nvidia,pins = "ph3";
    nvidia,function = "safe";
    nvidia,enable-input = <0>;
    nvidia,pull = <0>;
    nvidia,tristate = <0>;
   };

   ph4 {
    nvidia,pins = "ph4";
    nvidia,function = "safe";
    nvidia,enable-input = <1>;
    nvidia,pull = <2>;
    nvidia,tristate = <0>;
   };

   ph5 {
    nvidia,pins = "ph5";
    nvidia,function = "safe";
    nvidia,enable-input = <0>;
    nvidia,pull = <0>;
    nvidia,tristate = <0>;
   };

   pg2 {
    nvidia,pins = "pg2";
    nvidia,function = "safe";
    nvidia,enable-input = <1>;
    nvidia,pull = <1>;
    nvidia,tristate = <0>;
   };

   pg3 {
    nvidia,pins = "pg3";
    nvidia,function = "safe";
    nvidia,enable-input = <1>;
    nvidia,pull = <1>;
    nvidia,tristate = <0>;
   };

   pk1 {
    nvidia,pins = "pk1";
    nvidia,function = "safe";
    nvidia,enable-input = <0>;
    nvidia,pull = <0>;
    nvidia,tristate = <0>;
   };

   pj0 {
    nvidia,pins = "pj0";
    nvidia,function = "safe";
    nvidia,enable-input = <1>;
    nvidia,pull = <2>;
    nvidia,tristate = <0>;
   };

   pk3 {
    nvidia,pins = "pk3";
    nvidia,function = "safe";
    nvidia,enable-input = <1>;
    nvidia,pull = <2>;
    nvidia,tristate = <0>;
   };

   pk4 {
    nvidia,pins = "pk4";
    nvidia,function = "safe";
    nvidia,enable-input = <0>;
    nvidia,pull = <0>;
    nvidia,tristate = <0>;
   };

   pk2 {
    nvidia,pins = "pk2";
    nvidia,function = "safe";
    nvidia,enable-input = <1>;
    nvidia,pull = <2>;
    nvidia,tristate = <0>;
   };

   pi6 {
    nvidia,pins = "pi6";
    nvidia,function = "safe";
    nvidia,enable-input = <1>;
    nvidia,pull = <2>;
    nvidia,tristate = <0>;
   };

   pi2 {
    nvidia,pins = "pi2";
    nvidia,function = "safe";
    nvidia,enable-input = <0>;
    nvidia,pull = <0>;
    nvidia,tristate = <0>;
   };

   pi5 {
    nvidia,pins = "pi5";
    nvidia,function = "safe";
    nvidia,enable-input = <1>;
    nvidia,pull = <2>;
    nvidia,tristate = <0>;
   };

   pi4 {
    nvidia,pins = "pi4";
    nvidia,function = "safe";
    nvidia,enable-input = <0>;
    nvidia,pull = <0>;
    nvidia,tristate = <0>;
   };

   pc7 {
    nvidia,pins = "pc7";
    nvidia,function = "safe";
    nvidia,enable-input = <1>;
    nvidia,pull = <2>;
    nvidia,tristate = <0>;
   };

   pi0 {
    nvidia,pins = "pi0";
    nvidia,function = "safe";
    nvidia,enable-input = <0>;
    nvidia,pull = <0>;
    nvidia,tristate = <0>;
   };

   clk2_req_pcc5 {
    nvidia,pins = "clk2_req_pcc5";
    nvidia,function = "safe";
    nvidia,enable-input = <0>;
    nvidia,pull = <0>;
    nvidia,tristate = <0>;
   };

   sdmmc1_wp_n_pv3 {
    nvidia,pins = "sdmmc1_wp_n_pv3";
    nvidia,function = "safe";
    nvidia,enable-input = <1>;
    nvidia,pull = <2>;
    nvidia,tristate = <0>;
   };

   kb_col0_pq0 {
    nvidia,pins = "kb_col0_pq0";
    nvidia,function = "safe";
    nvidia,enable-input = <1>;
    nvidia,pull = <2>;
    nvidia,tristate = <0>;
   };

   kb_col1_pq1 {
    nvidia,pins = "kb_col1_pq1";
    nvidia,function = "safe";
    nvidia,enable-input = <1>;
    nvidia,pull = <0>;
    nvidia,tristate = <0>;
   };

   kb_col2_pq2 {
    nvidia,pins = "kb_col2_pq2";
    nvidia,function = "safe";
    nvidia,enable-input = <1>;
    nvidia,pull = <2>;
    nvidia,tristate = <0>;
   };

   kb_col5_pq5 {
    nvidia,pins = "kb_col5_pq5";
    nvidia,function = "safe";
    nvidia,enable-input = <1>;
    nvidia,pull = <2>;
    nvidia,tristate = <0>;
   };

   kb_col6_pq6 {
    nvidia,pins = "kb_col6_pq6";
    nvidia,function = "safe";
    nvidia,enable-input = <1>;
    nvidia,pull = <2>;
    nvidia,tristate = <0>;
   };

   kb_col7_pq7 {
    nvidia,pins = "kb_col7_pq7";
    nvidia,function = "safe";
    nvidia,enable-input = <1>;
    nvidia,pull = <2>;
    nvidia,tristate = <0>;
   };

   kb_row0_pr0 {
    nvidia,pins = "kb_row0_pr0";
    nvidia,function = "safe";
    nvidia,enable-input = <0>;
    nvidia,pull = <0>;
    nvidia,tristate = <0>;
   };

   kb_row1_pr1 {
    nvidia,pins = "kb_row1_pr1";
    nvidia,function = "safe";
    nvidia,enable-input = <0>;
    nvidia,pull = <0>;
    nvidia,tristate = <0>;
   };

   kb_row11_ps3 {
    nvidia,pins = "kb_row11_ps3";
    nvidia,function = "safe";
    nvidia,enable-input = <0>;
    nvidia,pull = <0>;
    nvidia,tristate = <0>;
   };

   kb_row12_ps4 {
    nvidia,pins = "kb_row12_ps4";
    nvidia,function = "safe";
    nvidia,enable-input = <0>;
    nvidia,pull = <0>;
    nvidia,tristate = <0>;
   };

   kb_row13_ps5 {
    nvidia,pins = "kb_row13_ps5";
    nvidia,function = "safe";
    nvidia,enable-input = <0>;
    nvidia,pull = <0>;
    nvidia,tristate = <0>;
   };

   kb_row14_ps6 {
    nvidia,pins = "kb_row14_ps6";
    nvidia,function = "safe";
    nvidia,enable-input = <0>;
    nvidia,pull = <0>;
    nvidia,tristate = <0>;
   };

   kb_row2_pr2 {
    nvidia,pins = "kb_row2_pr2";
    nvidia,function = "safe";
    nvidia,enable-input = <0>;
    nvidia,pull = <0>;
    nvidia,tristate = <0>;
   };

   kb_row4_pr4 {
    nvidia,pins = "kb_row4_pr4";
    nvidia,function = "safe";
    nvidia,enable-input = <1>;
    nvidia,pull = <2>;
    nvidia,tristate = <0>;
   };

   kb_row5_pr5 {
    nvidia,pins = "kb_row5_pr5";
    nvidia,function = "safe";
    nvidia,enable-input = <0>;
    nvidia,pull = <0>;
    nvidia,tristate = <0>;
   };

   kb_row7_pr7 {
    nvidia,pins = "kb_row7_pr7";
    nvidia,function = "safe";
    nvidia,enable-input = <1>;
    nvidia,pull = <2>;
    nvidia,tristate = <0>;
   };

   kb_row8_ps0 {
    nvidia,pins = "kb_row8_ps0";
    nvidia,function = "safe";
    nvidia,enable-input = <1>;
    nvidia,pull = <2>;
    nvidia,tristate = <0>;
   };

   clk3_req_pee1 {
    nvidia,pins = "clk3_req_pee1";
    nvidia,function = "safe";
    nvidia,enable-input = <0>;
    nvidia,pull = <0>;
    nvidia,tristate = <0>;
   };

   pu0 {
    nvidia,pins = "pu0";
    nvidia,function = "safe";
    nvidia,enable-input = <0>;
    nvidia,pull = <0>;
    nvidia,tristate = <0>;
   };

   pu1 {
    nvidia,pins = "pu1";
    nvidia,function = "safe";
    nvidia,enable-input = <1>;
    nvidia,pull = <1>;
    nvidia,tristate = <0>;
   };

   pu2 {
    nvidia,pins = "pu2";
    nvidia,function = "safe";
    nvidia,enable-input = <1>;
    nvidia,pull = <1>;
    nvidia,tristate = <0>;
   };

   pu3 {
    nvidia,pins = "pu3";
    nvidia,function = "safe";
    nvidia,enable-input = <0>;
    nvidia,pull = <0>;
    nvidia,tristate = <0>;
   };

   pu4 {
    nvidia,pins = "pu4";
    nvidia,function = "safe";
    nvidia,enable-input = <0>;
    nvidia,pull = <0>;
    nvidia,tristate = <0>;
   };

   pu5 {
    nvidia,pins = "pu5";
    nvidia,function = "safe";
    nvidia,enable-input = <1>;
    nvidia,pull = <2>;
    nvidia,tristate = <0>;
   };

   pu6 {
    nvidia,pins = "pu6";
    nvidia,function = "safe";
    nvidia,enable-input = <1>;
    nvidia,pull = <2>;
    nvidia,tristate = <0>;
   };

   hdmi_int_pn7 {
    nvidia,pins = "hdmi_int_pn7";
    nvidia,function = "safe";
    nvidia,enable-input = <1>;
    nvidia,pull = <1>;
    nvidia,tristate = <0>;
   };

   spdif_out_pk5 {
    nvidia,pins = "spdif_out_pk5";
    nvidia,function = "safe";
    nvidia,enable-input = <0>;
    nvidia,pull = <0>;
    nvidia,tristate = <0>;
   };

   spdif_in_pk6 {
    nvidia,pins = "spdif_in_pk6";
    nvidia,function = "safe";
    nvidia,enable-input = <0>;
    nvidia,pull = <0>;
    nvidia,tristate = <0>;
   };
  };

  pinmux_unused_lowpower: unused_lowpower {
   dap_mclk1_req_pee2 {
    nvidia,pins = "dap_mclk1_req_pee2";
    nvidia,function = "safe";
    nvidia,enable-input = <0>;
    nvidia,pull = <1>;
    nvidia,tristate = <1>;
   };

   dap3_din_pp1 {
    nvidia,pins = "dap3_din_pp1";
    nvidia,function = "safe";
    nvidia,enable-input = <0>;
    nvidia,pull = <1>;
    nvidia,tristate = <1>;
   };

   dap3_dout_pp2 {
    nvidia,pins = "dap3_dout_pp2";
    nvidia,function = "safe";
    nvidia,enable-input = <0>;
    nvidia,pull = <1>;
    nvidia,tristate = <1>;
   };

   dap3_fs_pp0 {
    nvidia,pins = "dap3_fs_pp0";
    nvidia,function = "safe";
    nvidia,enable-input = <0>;
    nvidia,pull = <1>;
    nvidia,tristate = <1>;
   };

   dap3_sclk_pp3 {
    nvidia,pins = "dap3_sclk_pp3";
    nvidia,function = "safe";
    nvidia,enable-input = <0>;
    nvidia,pull = <1>;
    nvidia,tristate = <1>;
   };

   ulpi_data0_po1 {
    nvidia,pins = "ulpi_data0_po1";
    nvidia,function = "safe";
    nvidia,enable-input = <0>;
    nvidia,pull = <1>;
    nvidia,tristate = <1>;
   };

   ulpi_data3_po4 {
    nvidia,pins = "ulpi_data3_po4";
    nvidia,function = "safe";
    nvidia,enable-input = <0>;
    nvidia,pull = <1>;
    nvidia,tristate = <1>;
   };

   pi1 {
    nvidia,pins = "pi1";
    nvidia,function = "safe";
    nvidia,enable-input = <0>;
    nvidia,pull = <1>;
    nvidia,tristate = <1>;
   };

   pex_l0_clkreq_n_pdd2 {
    nvidia,pins = "pex_l0_clkreq_n_pdd2";
    nvidia,function = "safe";
    nvidia,enable-input = <0>;
    nvidia,pull = <1>;
    nvidia,tristate = <1>;
   };

   pex_l0_rst_n_pdd1 {
    nvidia,pins = "pex_l0_rst_n_pdd1";
    nvidia,function = "safe";
    nvidia,enable-input = <0>;
    nvidia,pull = <1>;
    nvidia,tristate = <1>;
   };

   pex_l1_clkreq_n_pdd6 {
    nvidia,pins = "pex_l1_clkreq_n_pdd6";
    nvidia,function = "safe";
    nvidia,enable-input = <0>;
    nvidia,pull = <1>;
    nvidia,tristate = <1>;
   };

   pex_l1_rst_n_pdd5 {
    nvidia,pins = "pex_l1_rst_n_pdd5";
    nvidia,function = "safe";
    nvidia,enable-input = <0>;
    nvidia,pull = <1>;
    nvidia,tristate = <1>;
   };

   pex_wake_n_pdd3 {
    nvidia,pins = "pex_wake_n_pdd3";
    nvidia,function = "safe";
    nvidia,enable-input = <0>;
    nvidia,pull = <1>;
    nvidia,tristate = <1>;
   };

   pff2 {
    nvidia,pins = "pff2";
    nvidia,function = "safe";
    nvidia,enable-input = <0>;
    nvidia,pull = <1>;
    nvidia,tristate = <1>;
   };

   kb_col3_pq3 {
    nvidia,pins = "kb_col3_pq3";
    nvidia,function = "safe";
    nvidia,enable-input = <0>;
    nvidia,pull = <1>;
    nvidia,tristate = <1>;
   };

   kb_row16_pt0 {
    nvidia,pins = "kb_row16_pt0";
    nvidia,function = "safe";
    nvidia,enable-input = <0>;
    nvidia,pull = <1>;
    nvidia,tristate = <1>;
   };

   kb_row17_pt1 {
    nvidia,pins = "kb_row17_pt1";
    nvidia,function = "safe";
    nvidia,enable-input = <0>;
    nvidia,pull = <1>;
    nvidia,tristate = <1>;
   };

   owr {
    nvidia,pins = "owr";
    nvidia,function = "safe";
    nvidia,enable-input = <0>;
    nvidia,pull = <1>;
    nvidia,tristate = <1>;
   };
  };

  drive_default: drive {
   drive_sdio1 {
    nvidia,pins = "drive_sdio1";
    nvidia,high-speed-mode = <1>;
    nvidia,schmitt = <0>;
    nvidia,pull-down-strength = <32>;
    nvidia,pull-up-strength = <42>;
    nvidia,slew-rate-rising = <0>;
    nvidia,slew-rate-falling = <0>;
   };

   drive_sdio3 {
    nvidia,pins = "drive_sdio3";
    nvidia,high-speed-mode = <1>;
    nvidia,schmitt = <0>;
    nvidia,pull-down-strength = <20>;
    nvidia,pull-up-strength = <36>;
    nvidia,slew-rate-rising = <0>;
    nvidia,slew-rate-falling = <0>;
   };

   drive_gma {
    nvidia,pins = "drive_gma";
    nvidia,high-speed-mode = <1>;
    nvidia,schmitt = <0>;
    nvidia,low-power-mode = <3>;
    nvidia,pull-down-strength = <1>;
    nvidia,pull-up-strength = <2>;
    nvidia,slew-rate-rising = <0>;
    nvidia,slew-rate-falling = <0>;
    nvidia,drive-type = <1>;
   };
  };

  gen1_i2c_hs_drive: gen1_i2c_drive {
   drive_dbg {
    nvidia,pins = "drive_dbg";
    nvidia,high-speed-mode = <1>;
    nvidia,schmitt = <1>;
    nvidia,low-power-mode = <3>;
    nvidia,pull-down-strength = <0>;
    nvidia,pull-up-strength = <0>;
    nvidia,slew-rate-rising = <0>;
    nvidia,slew-rate-falling = <0>;
   };
  };

  gen2_i2c_hs_drive: gen2_i2c_drive {
   drive_at5 {
    nvidia,pins = "drive_at5";
    nvidia,high-speed-mode = <1>;
    nvidia,schmitt = <1>;
    nvidia,low-power-mode = <3>;
    nvidia,pull-down-strength = <0>;
    nvidia,pull-up-strength = <0>;
    nvidia,slew-rate-rising = <0>;
    nvidia,slew-rate-falling = <0>;
   };
  };

  cam_i2c_hs_drive: cam_i2c_drive {
   drive_gme {
    nvidia,pins = "drive_gme";
    nvidia,high-speed-mode = <1>;
    nvidia,schmitt = <1>;
    nvidia,low-power-mode = <3>;
    nvidia,pull-down-strength = <0>;
    nvidia,pull-up-strength = <0>;
    nvidia,slew-rate-rising = <0>;
    nvidia,slew-rate-falling = <0>;
   };
  };

  ddc_i2c_hs_drive: ddc_i2c_drive {
   drive_ddc {
    nvidia,pins = "drive_ddc";
    nvidia,high-speed-mode = <1>;
    nvidia,schmitt = <1>;
    nvidia,low-power-mode = <3>;
    nvidia,pull-down-strength = <0>;
    nvidia,pull-up-strength = <0>;
    nvidia,slew-rate-rising = <0>;
    nvidia,slew-rate-falling = <0>;
   };
  };

  pwr_i2c_hs_drive: pwr_i2c_drive {
   drive_ao1 {
    nvidia,pins = "drive_ao1";
    nvidia,high-speed-mode = <1>;
    nvidia,schmitt = <1>;
    nvidia,low-power-mode = <3>;
    nvidia,pull-down-strength = <0>;
    nvidia,pull-up-strength = <0>;
    nvidia,slew-rate-rising = <0>;
    nvidia,slew-rate-falling = <0>;
   };
  };
 };
};
# 9 "arch/arm/boot/dts/tegra124-ardbeg-e1780-1000-a03-common.dtsi" 2
# 1 "arch/arm/boot/dts/tegra124-platforms/tegra124-tn8-keys-e1780-1100-a02.dtsi" 1



/ {
 gpio-keys {
  compatible = "gpio-keys";

  camera_focus {
   label = "Camera Focus";
   gpios = <&gpio ((16 * 8) + 2) 1>;
   linux,code = <0x210>;
  };

  home {
   label = "Home";
   gpios = <&gpio ((8 * 8) + 5) 1>;
   linux,code = <102>;
  };

  power {
   label = "Power";
   gpios = <&gpio ((16 * 8) + 0) 1>;
   linux,code = <116>;
   gpio-key,wakeup;
  };

  volume_down {
   label = "Volume Down";
   gpios = <&gpio ((16 * 8) + 7) 1>;
   linux,code = <114>;
  };

  volume_up {
   label = "Volume Up";
   gpios = <&gpio ((16 * 8) + 6) 1>;
   linux,code = <115>;
  };
 };
};
# 10 "arch/arm/boot/dts/tegra124-ardbeg-e1780-1000-a03-common.dtsi" 2
# 1 "arch/arm/boot/dts/tegra124-platforms/tegra124-tn8-camera-e1780-a00.dtsi" 1
# 1 "/media/madman/Extended_Linux/21.8_l4t_build/kernel/arch/arm/boot/dts/include/dt-bindings/media/camera.h" 1
# 2 "arch/arm/boot/dts/tegra124-platforms/tegra124-tn8-camera-e1780-a00.dtsi" 2

/ {
 camera-pcl {
  compatible = "nvidia,tegra124-camera", "simple-bus";
  configuration = <0xAA55AA55>;

  modules {
   module1: module1@modules {
    compatible = "sensor,rear";
    badge_info = "e1793_rear_camera";

    sensor {
     profile = <&ov5693_1>;
     platformdata = "ardbeg_ov5693_pdata";
    };
    focuser {
     profile = <&ad5823_1>;
     platformdata = "ardbeg_ad5823_pdata";
    };
    flash {
     profile = <&as3648_1>;
     platformdata = "ardbeg_as3648_pdata";
    };
   };
   module2: module2@modules {
    compatible = "sensor,front";
    badge_info = "e1793_front_camera";

    sensor {
     profile = <&mt9m114_1>;
     platformdata = "ardbeg_mt9m114_pdata";
    };
   };
   module3: module3@modules {
    compatible = "sensor,rear";
    badge_info = "e1823_rear_camera";

    sensor {
     profile = <&imx135_1>;
     platformdata = "ardbeg_imx135_pdata";
    };
    focuser {
     profile = <&dw9718_1>;
     platformdata = "ardbeg_dw9718_pdata";
    };
    flash {
     profile = <&as3648_1>;
     platformdata = "ardbeg_as3648_pdata";
    };
   };
   module4: module4@modules {
    compatible = "sensor,front";
    badge_info = "e1823_front_camera";

    sensor {
     profile = <&ar0261_1>;
     platformdata = "ardbeg_ar0261_pdata";
    };
   };
   module5: module5@modules {
    compatible = "sensor,front";
    badge_info = "loki_front_camera_brd";

    sensor {
     profile = <&ov7695_1>;
     platformdata = "ardbeg_ov7695_pdata";
    };
   };
   module6: module6@modules {
    compatible = "sensor,rear";
    badge_info = "e1633_rear_camera";

    sensor {
     profile = <&ar0330_1>;
     platformdata = "ardbeg_ar0330_pdata";
    };
   };
   module7: module7@modules {
    compatible = "sensor,front";
    badge_info = "e1633_front_camera";

    sensor {
     profile = <&ar0330_2>;
     platformdata = "ardbeg_ar0330_front_pdata";
    };
   };
  };

  profiles {
   ov5693_1: ov5693@2_0010 {
    index = <1>;
    chipname = "pcl_OV5693";
    type = "sensor";
    guid = "s_OV5693";
    position = <0>;
    bustype = "i2c";
    busnum = <2>;
    addr = <0x10>;
    datalen = <2>;
    pinmuxgrp = <0xFFFF>;
    gpios = <3>;
    regulators = "avdd_ov5693", "vdd_af1", "dovdd";
    clocks = "mclk";
    drivername = "ov5693";
    detect = <0x0002 0x300A 0xFFFF 0x5690>;
    devid = <0x5693>;
    poweron = <
     (0xf0000000 | 50) 10000
     (0xf0000000 | 31) 221
     (0xf0000000 | 2) 1
     (0xf0000000 | 20) (0x80000000 + 0)
     (0xf0000000 | 20) (0x80000000 + 1)
     (0xf0000000 | 20) (0x80000000 + 2)
     (0xf0000000 | 2) 1
     (0xf0000000 | 30) 221
     (0xf0000000 | 2) 10
     (0xf0000000 | 9) 0
     >;
    poweroff = <
     (0xf0000000 | 50) 0
     (0xf0000000 | 31) 221
     (0xf0000000 | 1) 10
     (0xf0000000 | 20) 2
     (0xf0000000 | 20) 1
     (0xf0000000 | 20) 0
     (0xf0000000 | 9) 0
     >;
   };
   mt9m114_1: mt9m114@2_0048 {
    index = <2>;
    chipname = "pcl_MT9M114";
    type = "sensor";
    guid = "sMT9M114";
    position = <1>;
    bustype = "i2c";
    busnum = <2>;
    addr = <0x48>;
    datalen = <2>;
    pinmuxgrp = <0xFFFF>;
    gpios = <3>;
    regulators = "vana", "vif";
    clocks = "mclk2";
    drivername = "mt9m114";
    detect = <0x0002 0x0000 0xFFFF 0x2481>;
    devid = <0x1040>;
    poweron = <
     (0xf0000000 | 50) 10000
     (0xf0000000 | 31) 219
     (0xf0000000 | 30) 222
     (0xf0000000 | 20) (0x80000000 + 0)
     (0xf0000000 | 20) (0x80000000 + 1)
     (0xf0000000 | 2) 10
     (0xf0000000 | 31) 222
     (0xf0000000 | 30) 219
     (0xf0000000 | 2) 20
     (0xf0000000 | 9) 0
     >;
    poweroff = <
     (0xf0000000 | 50) 0
     (0xf0000000 | 30) 222
     (0xf0000000 | 31) 219
     (0xf0000000 | 1) 10
     (0xf0000000 | 20) 1
     (0xf0000000 | 20) 0
     (0xf0000000 | 9) 0
     >;
   };
   ad5823_1: ad5823@2_000c {
    index = <3>;
    chipname = "pcl_AD5823";
    type = "focuser";
    guid = "f_AD5823";
    position = <0>;
    bustype = "i2c";
    busnum = <2>;
    addr = <0xc>;
    datalen = <1>;
    pinmuxgrp = <0xFFFF>;
    gpios = <3>;
    regulators = "vdd", "vdd_i2c";
    drivername = "ad5823";
    detect = <0x0002 0x0006 0xFFFF 0x0010>;
    devid = <0x5823>;
    poweron = <
     (0xf0000000 | 20) (0x80000000 + 1)
     (0xf0000000 | 20) (0x80000000 + 0)
     (0xf0000000 | 1) 10
     (0xf0000000 | 30) 223
     (0xf0000000 | 1) 10
     (0xf0000000 | 9) 0
     >;
    poweroff = <
     (0xf0000000 | 20) 0
     (0xf0000000 | 20) 1
     (0xf0000000 | 31) 223
     (0xf0000000 | 1) 10
     (0xf0000000 | 9) 0
     >;
   };
   as3648_1: as3648@2_0030 {
    index = <4>;
    chipname = "pcl_AS3648";
    type = "flash";
    guid = "l_NVCAM0";
    position = <0>;
    bustype = "i2c";
    busnum = <2>;
    addr = <0x30>;
    datalen = <1>;
    pinmuxgrp = <0xFFFF>;
    gpios = <3>;
    regulators = "vi2c", "vin";
    drivername = "as3648";
    detect = <0x0001 0x0000 0x00F0 0x00b0>;
    devid = <0x3648>;
    poweron = <
     (0xf0000000 | 20) (0x80000000 + 1)
     (0xf0000000 | 20) (0x80000000 + 0)
     (0xf0000000 | 1) 1000
     (0xf0000000 | 9) 0
     >;
    poweroff = <
     (0xf0000000 | 20) 0
     (0xf0000000 | 20) 1
     (0xf0000000 | 1) 10
     (0xf0000000 | 9) 0
     >;
   };
   imx135_1: imx135@2_0010 {
    index = <5>;
    chipname = "pcl_IMX135";
    type = "sensor";
    guid = "s_IMX135";
    position = <0>;
    bustype = "i2c";
    busnum = <2>;
    addr = <0x10>;
    datalen = <2>;
    pinmuxgrp = <0xFFFF>;
    gpios = <3>;
    regulators = "vana", "vdig_lv", "vif";
    clocks = "mclk";
    drivername = "imx135";
    detect = <0x0002 0x0016 0xFFFF 0x0135>;
    devid = <0x0135>;
    poweron = <
     (0xf0000000 | 50) 10000
     (0xf0000000 | 31) 221
     (0xf0000000 | 1) 10
     (0xf0000000 | 20) (0x80000000 + 2)
     (0xf0000000 | 20) (0x80000000 + 1)
     (0xf0000000 | 20) (0x80000000 + 0)
     (0xf0000000 | 2) 5
     (0xf0000000 | 30) 221
     (0xf0000000 | 1) 300
     (0xf0000000 | 9) 0
     >;
    poweroff = <
     (0xf0000000 | 50) 0
     (0xf0000000 | 31) 221
     (0xf0000000 | 1) 10
     (0xf0000000 | 20) 2
     (0xf0000000 | 20) 1
     (0xf0000000 | 20) 0
     (0xf0000000 | 9) 0
     >;
   };
   ar0261_1: ar0261@2_0036 {
    index = <6>;
    chipname = "pcl_AR0261";
    type = "sensor";
    guid = "s_AR0261";
    position = <1>;
    bustype = "i2c";
    busnum = <2>;
    addr = <0x36>;
    datalen = <2>;
    pinmuxgrp = <0xFFFF>;
    gpios = <3>;
    regulators = "vana", "vdig", "vif";
    clocks = "mclk2";
    drivername = "ar0261";
    detect = <0x0002 0x0003 0xFFFF 0x060A>;
    devid = <0x0261>;
    poweron = <
     (0xf0000000 | 50) 10000
     (0xf0000000 | 31) 219
     (0xf0000000 | 20) (0x80000000 + 0)
     (0xf0000000 | 20) (0x80000000 + 1)
     (0xf0000000 | 20) (0x80000000 + 2)
     (0xf0000000 | 2) 40
     (0xf0000000 | 30) 219
     (0xf0000000 | 2) 20
     (0xf0000000 | 9) 0
     >;
    poweroff = <
     (0xf0000000 | 50) 0
     (0xf0000000 | 31) 219
     (0xf0000000 | 1) 10
     (0xf0000000 | 20) 2
     (0xf0000000 | 20) 1
     (0xf0000000 | 20) 0
     (0xf0000000 | 9) 0
     >;
   };
   ov7695_1: ov7695@2_0021 {
    index = <7>;
    chipname = "pcl_OV7695";
    type = "sensor";
    guid = "s_OV7695";
    position = <1>;
    bustype = "i2c";
    busnum = <2>;
    addr = <0x21>;
    datalen = <2>;
    pinmuxgrp = <0xFFFF>;
    gpios = <3>;
    regulators = "vana", "vif2";
    clocks = "mclk2";
    drivername = "ov7695";
    detect = <0x0002 0x300A 0xFFFF 0x7695>;
    devid = <0x7695>;
    poweron = <
     (0xf0000000 | 50) 10000
     (0xf0000000 | 31) 222
     (0xf0000000 | 20) (0x80000000 + 0)
     (0xf0000000 | 20) (0x80000000 + 1)
     (0xf0000000 | 2) 40
     (0xf0000000 | 30) 222
     (0xf0000000 | 2) 10
     (0xf0000000 | 9) 0
     >;
    poweroff = <
     (0xf0000000 | 50) 0
     (0xf0000000 | 31) 222
     (0xf0000000 | 1) 10
     (0xf0000000 | 20) 1
     (0xf0000000 | 20) 0
     (0xf0000000 | 9) 0
     >;
   };
   dw9718_1: dw9718@2_000c {
    index = <8>;
    chipname = "pcl_DW9718";
    type = "focuser";
    guid = "f_NVCAM0";
    position = <0>;
    bustype = "i2c";
    busnum = <2>;
    addr = <0xc>;
    datalen = <1>;
    pinmuxgrp = <0xFFFF>;
    gpios = <3>;
    regulators = "vdd", "vdd_i2c";
    drivername = "dw9718";
    detect = <0x0002 0x0004 0xFFFF 0x0060>;
    devid = <0x9718>;
    poweron = <
     (0xf0000000 | 20) (0x80000000 + 1)
     (0xf0000000 | 20) (0x80000000 + 0)
     (0xf0000000 | 1) 10
     (0xf0000000 | 30) 223
     (0xf0000000 | 1) 10
     (0xf0000000 | 9) 0
     >;
    poweroff = <
     (0xf0000000 | 20) 0
     (0xf0000000 | 20) 1
     (0xf0000000 | 31) 223
     (0xf0000000 | 1) 10
     (0xf0000000 | 9) 0
     >;
   };
   ar0330_1: ar0330@2_0010 {
    index = <9>;
    chipname = "pcl_AR0330";
    type = "sensor";
    guid = "s_AR0330";
    position = <0>;
    bustype = "i2c";
    busnum = <2>;
    addr = <0x10>;
    datalen = <2>;
    pinmuxgrp = <0xFFFF>;
    gpios = <3>;
    regulators = "vana", "vdig", "vif";
    clocks = "mclk";
    drivername = "ar0330";
    detect = <0x0002 0x3000 0xFFFF 0x2604>;
    devid = <0x0330>;
    poweron = <
     (0xf0000000 | 50) 10000
     (0xf0000000 | 31) 219
     (0xf0000000 | 20) (0x80000000 + 0)
     (0xf0000000 | 20) (0x80000000 + 1)
     (0xf0000000 | 20) (0x80000000 + 2)
     (0xf0000000 | 2) 40
     (0xf0000000 | 30) 219
     (0xf0000000 | 2) 20
     (0xf0000000 | 9) 0
     >;
    poweroff = <
     (0xf0000000 | 50) 0
     (0xf0000000 | 31) 219
     (0xf0000000 | 1) 10
     (0xf0000000 | 20) 2
     (0xf0000000 | 20) 1
     (0xf0000000 | 20) 0
     (0xf0000000 | 9) 0
     >;
   };
   ar0330_2: ar0330@2_0018 {
    index = <11>;
    chipname = "pcl_AR0330";
    type = "sensor";
    guid = "sAR0330f";
    position = <1>;
    bustype = "i2c";
    busnum = <2>;
    addr = <0x18>;
    datalen = <2>;
    pinmuxgrp = <0xFFFF>;
    gpios = <3>;
    regulators = "avdd_cam1_cam", "vdd_1v2_cam", "vdd_cam1_1v8_cam";
    clocks = "mclk";
    drivername = "ar0330";
    detect = <0x0002 0x3000 0xFFFF 0x2604>;
    devid = <0x0330>;
    poweron = <
     (0xf0000000 | 50) 10000
     (0xf0000000 | 31) 219
     (0xf0000000 | 20) (0x80000000 + 0)
     (0xf0000000 | 20) (0x80000000 + 1)
     (0xf0000000 | 20) (0x80000000 + 2)
     (0xf0000000 | 2) 40
     (0xf0000000 | 30) 219
     (0xf0000000 | 2) 20
     (0xf0000000 | 9) 0
     >;
    poweroff = <
     (0xf0000000 | 50) 0
     (0xf0000000 | 31) 219
     (0xf0000000 | 1) 10
     (0xf0000000 | 20) 2
     (0xf0000000 | 20) 1
     (0xf0000000 | 20) 0
     (0xf0000000 | 9) 0
     >;
   };
  };
 };
};
# 11 "arch/arm/boot/dts/tegra124-ardbeg-e1780-1000-a03-common.dtsi" 2

/ {
 model = "NVIDIA Tegra124 Ardbeg";
 compatible = "nvidia,ardbeg", "nvidia,tegra124";
 nvidia,boardids = "1780:1000:3:B:3";

 #address-cells = <2>;
 #size-cells = <2>;

 chosen {
  bootargs = "tegraid=40.0.0.00.00 vmalloc=256M video=tegrafb console=ttyS0,115200n8 earlyprintk";
  linux,initrd-start = <0x85000000>;
  linux,initrd-end = <0x851bc400>;
 };

        serial@70006000 {
                compatible = "nvidia,tegra114-hsuart";
                status = "okay";
        };

        serial@70006040 {
                compatible = "nvidia,tegra114-hsuart";
                status = "okay";
        };

        serial@70006200 {
                compatible = "nvidia,tegra114-hsuart";
                status = "okay";
        };

 memory@0x80000000 {
  device_type = "memory";
  reg = <0x0 0x80000000 0x0 0x80000000>;
 };

 i2c@7000c400 {
  bq20z75@0b {
   compatible = "sbs,sbs-battery";
   reg = <0x0b>;
   status = "disabled";
   sbs,i2c-retry-count = <2>;
   sbs,poll-retry-count = <100>;
  };

  bq2477x@6a {
   compatible = "ti,bq2477x";
   reg = <0x6a>;
   status = "disabled";
   ti,dac-ichg = <2240>;
   ti,dac-v = <9008>;
   ti,dac-minsv = <4608>;
   ti,dac-iin = <4992>;
   ti,wdt-refresh-timeout = <40>;
   ti,charger-detect-gpio-active-low = <1>;
   charger-detect-gpio = <&gpio ((9 * 8) + 0) 0>;
  };
 };

 i2c@7000d000 {
  nvidia,bit-banging-xfer-after-shutdown;
 };

 spi@7000d400 {
  status = "okay";
  spi-max-frequency = <25000000>;
 };

 spi@7000da00 {
  status = "okay";
  spi-max-frequency = <25000000>;
 };

 pmc {
  status = "okay";
  nvidia,invert-interrupt;
  nvidia,suspend-mode = <0>;
  nvidia,cpu-pwr-good-time = <500>;
  nvidia,cpu-pwr-off-time = <300>;
  nvidia,core-pwr-good-time = <3845 3845>;
  nvidia,core-pwr-off-time = <2000>;
  nvidia,core-power-req-active-high;
  nvidia,sys-clock-req-active-high;
 };

 stm8t143 {
  compatible = "stm,stm8t143";
  pout-gpio = <&gpio 190 0>;
  tout-gpio = <&gpio 112 0>;
 };

 xusb@70090000 {


  nvidia,gpio_ss1_sata = <0>;
  nvidia,portmap = <0x703>;
  nvidia,ss_portmap = <0x20>;
  nvidia,lane_owner = <6>;
  nvidia,ulpicap = <0>;
  nvidia,supply_utmi_vbuses = "usb_vbus0", "usb_vbus1", "usb_vbus2";
  nvidia,supply_s3p3v = "hvdd_usb";
  nvidia,supply_s1p8v = "avdd_pll_utmip";
  nvidia,supply_vddio_hsic = "vddio_hsic";
  nvidia,supply_s1p05v = "avddio_usb";

  nvidia,hsic0 = /bits/8 <0x1 0x1 0x8 0xa 0 0 1 0x22 0>;
  status = "okay";
 };
};
# 4 "arch/arm/boot/dts/tegra124-ardbeg-e1792-1100-a00-00.dts" 2
# 1 "arch/arm/boot/dts/tegra124-platforms/tegra124-ardbeg-pmic-e1735-1000-a00.dtsi" 1

# 1 "/media/madman/Extended_Linux/21.8_l4t_build/kernel/arch/arm/boot/dts/include/dt-bindings/mfd/palmas.h" 1
# 3 "arch/arm/boot/dts/tegra124-platforms/tegra124-ardbeg-pmic-e1735-1000-a00.dtsi" 2
# 1 "/media/madman/Extended_Linux/21.8_l4t_build/kernel/arch/arm/boot/dts/include/dt-bindings/regulator/regulator.h" 1
# 4 "arch/arm/boot/dts/tegra124-platforms/tegra124-ardbeg-pmic-e1735-1000-a00.dtsi" 2

/ {
 i2c@7000d000 {
  palmas: tps65913@58 {
   compatible = "ti,palmas";
   reg = <0x58>;
   interrupts = <0 86 0>;

   #interrupt-cells = <2>;
   interrupt-controller;

   palmas_gpio: gpio {
    compatible = "ti,palmas-gpio";
    gpio-controller;
    #gpio-cells = <2>;
   };

   rtc {
    compatible = "ti,palmas-rtc";
    interrupt-parent = <&palmas>;
    interrupts = <8 0>;
   };

   pinmux {
    compatible = "ti,tps65913-pinctrl";
    pinctrl-names = "default";
    pinctrl-0 = <&palmas_default>;
    ti,palmas-enable-dvfs1;

    palmas_default: pinmux {
     powergood {
      pins = "powergood";
      function = "powergood";
     };

     vac {
      pins = "vac";
      function = "vac";
     };

     pin_gpio0 {
      pins = "gpio0";
      function = "id";
      bias-pull-up;
     };

     pin_gpio1 {
      pins = "gpio1";
      function = "vbus_det";
     };

     pin_gpio2_3_4_6_7 {
      pins = "gpio2", "gpio3", "gpio4", "gpio6", "gpio7";
      function = "gpio";
     };

     pin_gpio5 {
      pins = "gpio5";
      function = "clk32kgaudio";
     };
    };
   };

   extcon {
    compatible = "ti,palmas-usb";
    extcon-name = "palmas-extcon";
    ti,wakeup;
    ti,enable-id-detection;
    ti,enable-vbus-detection;
   };

   power_pm {
    compatible = "ti,palmas-pm";
    system-pmic-power-off;
    system-pmic-power-reset;
   };

   clock {
    compatible = "ti,palmas-clk";

    clk32k_kg {
     ti,clock-boot-enable;
    };

    clk32k_kg_audio {
     ti,clock-boot-enable;
    };
   };

   pmic {
    compatible = "ti,tps65913-pmic", "ti,palmas-pmic";
    ldo1-in-supply = <&palmas_smps7>;
    ldo2-in-supply = <&palmas_smps6>;
    ldo4-in-supply = <&palmas_smps6>;
    ldoln-in-supply = <&palmas_smps6>;

    regulators {
     smps123 {
      regulator-name = "vdd-gpu";
      regulator-min-microvolt = <650000>;
      regulator-max-microvolt = <1400000>;
      regulator-init-microvolt = <900000>;
      regulator-init-mode = <0x2>;
      regulator-boot-on;

      consumers {
       c0 {
        regulator-consumer-supply = "vdd_gpu";
       };
      };
     };

     smps45 {
      regulator-name = "vdd-core";
      regulator-min-microvolt = <700000>;
      regulator-max-microvolt = <1400000>;
      regulator-always-on;
      regulator-init-mode = <0x2>;
      regulator-boot-on;
      ti,roof-floor = <3>;

      consumers {
       c0 {
        regulator-consumer-supply = "vdd_core";
       };
      };
     };

     palmas_smps6: smps6 {
      regulator-name = "vddio-1v8";
      regulator-always-on;
      regulator-boot-on;
      regulator-init-mode = <0x2>;

      consumers {
       c0 {
        regulator-consumer-supply = "dbvdd";
        regulator-consumer-device = "tegra-snd-rt5639.0";
       };
       c1 {
        regulator-consumer-supply = "dbvdd";
        regulator-consumer-device = "tegra-snd-rt5645.0";
       };
       c2 {
        regulator-consumer-supply = "avdd";
        regulator-consumer-device = "tegra-snd-rt5639.0";
       };
       c3 {
        regulator-consumer-supply = "avdd";
        regulator-consumer-device = "tegra-snd-rt5645.0";
       };
       c4 {
        regulator-consumer-supply = "dmicvdd";
        regulator-consumer-device = "tegra-snd-rt5639.0";
       };
       c5 {
        regulator-consumer-supply = "dmicvdd";
        regulator-consumer-device = "tegra-snd-rt5645.0";
       };
       c6 {
        regulator-consumer-supply = "avdd_osc";
       };
       c7 {
        regulator-consumer-supply = "vddio_sys";
       };
       c8 {
        regulator-consumer-supply = "vddio_sys_2";
       };
       c9 {
        regulator-consumer-supply = "vddio_gmi";
       };
       c10 {
        regulator-consumer-supply = "pwrdet_nand";
       };
       c11 {
        regulator-consumer-supply = "vddio_sdmmc";
        regulator-consumer-device = "sdhci-tegra.0";
       };
       c12 {
        regulator-consumer-supply = "pwrdet_sdmmc1";
       };
       c13 {
        regulator-consumer-supply = "vddio_sdmmc";
        regulator-consumer-device = "sdhci-tegra.3";
       };
       c14 {
        regulator-consumer-supply = "pwrdet_sdmmc4";
       };
       c15 {
        regulator-consumer-supply = "avdd_pll_utmip";
        regulator-consumer-device = "tegra-udc.0";
       };
       c16 {
        regulator-consumer-supply = "avdd_pll_utmip";
        regulator-consumer-device = "tegra-ehci.0";
       };
       c17 {
        regulator-consumer-supply = "avdd_pll_utmip";
        regulator-consumer-device = "tegra-ehci.1";
       };
       c18 {
        regulator-consumer-supply = "avdd_pll_utmip";
        regulator-consumer-device = "tegra-ehci.2";
       };
       c19 {
        regulator-consumer-supply = "avdd_pll_utmip";
        regulator-consumer-device = "tegra-xhci";
       };
       c20 {
        regulator-consumer-supply = "vddio_audio";
       };
       c21 {
        regulator-consumer-supply = "pwrdet_audio";
       };
       c22 {
        regulator-consumer-supply = "vddio_uart";
       };
       c23 {
        regulator-consumer-supply = "pwrdet_uart";
       };
       c24 {
        regulator-consumer-supply = "vddio_bb";
       };
       c25 {
        regulator-consumer-supply = "pwrdet_bb";
       };
       c26 {
        regulator-consumer-supply = "vdd_1v8b";
        regulator-consumer-device = "0-0048";
       };
       c27 {
        regulator-consumer-supply = "vdd_dtv";
       };
       c28 {
        regulator-consumer-supply = "vdd_1v8_eeprom";
       };
       c29 {
        regulator-consumer-supply = "vddio_cam";
        regulator-consumer-device = "tegra_camera";
       };
       c30 {
        regulator-consumer-supply = "vddio_cam";
        regulator-consumer-device = "vi";
       };
       c31 {
        regulator-consumer-supply = "pwrdet_cam";
       };
       c32 {
        regulator-consumer-supply = "dvdd";
        regulator-consumer-device = "spi0.0";
       };
       c33 {
        regulator-consumer-supply = "vlogic";
        regulator-consumer-device = "0-0069";
       };
       c34 {
        regulator-consumer-supply = "vid";
        regulator-consumer-device = "0-000c";
       };
       c35 {
        regulator-consumer-supply = "vddio";
        regulator-consumer-device = "0-0077";
       };
       c36 {
        regulator-consumer-supply = "vdd_sata";
        regulator-consumer-device = "tegra-sata.0";
       };
       c37 {
        regulator-consumer-supply = "avdd_sata";
        regulator-consumer-device = "tegra-sata.0";
       };
       c38 {
        regulator-consumer-supply = "avdd_sata_pll";
        regulator-consumer-device = "tegra-sata.0";
       };
      };
     };

     palmas_smps7: smps7 {
      regulator-name = "vddio-ddr";
      regulator-always-on;
      regulator-boot-on;
      regulator-init-mode = <0x2>;

      consumers {
       c0 {
        regulator-consumer-supply = "vddio_ddr";
       };
       c1 {
        regulator-consumer-supply = "vddio_ddr_mclk";
       };
       c2 {
        regulator-consumer-supply = "vddio_ddr3";
       };
       c3 {
        regulator-consumer-supply = "vcore1_ddr3";
       };
      };
     };

     palmas_smps9: smps9 {
      regulator-name = "pex-hdmi";
      regulator-init-mode = <0x2>;

      consumers {
       c0 {
        regulator-consumer-supply = "avdd_hdmi";
        regulator-consumer-device = "tegradc.1";
       };
       c1 {
        regulator-consumer-supply = "avdd_hdmi_pll";
        regulator-consumer-device = "tegradc.1";
       };
       c2 {
        regulator-consumer-supply = "avdd_pex_pll";
        regulator-consumer-device = "tegra-pcie";
       };
       c3 {
        regulator-consumer-supply = "avddio_pex";
        regulator-consumer-device = "tegra-pcie";
       };
       c4 {
        regulator-consumer-supply = "dvddio_pex";
        regulator-consumer-device = "tegra-pcie";
       };
       c5 {
        regulator-consumer-supply = "avddio_usb";
        regulator-consumer-device = "tegra-xhci";
       };
       c6 {
        regulator-consumer-supply = "vddio_pex_sata";
        regulator-consumer-device = "tegra-sata.0";
       };
      };
     };

     palmas_ldo1: ldo1 {
      regulator-name = "avdd-pll";
      regulator-always-on;
      regulator-boot-on;
      ti,roof-floor = <3>;

      consumers {
       c0 {
        regulator-consumer-supply = "avdd_pll_m";
       };
       c1 {
        regulator-consumer-supply = "avdd_pll_ap_c2_c3";
       };
       c2 {
        regulator-consumer-supply = "avdd_pll_cud2dpd";
       };
       c3 {
        regulator-consumer-supply = "avdd_pll_c4";
       };
       c4 {
        regulator-consumer-supply = "avdd_lvds0_io";
       };
       c5 {
        regulator-consumer-supply = "vddio_ddr_hs";
       };
       c6 {
        regulator-consumer-supply = "avdd_pll_erefe";
       };
       c7 {
        regulator-consumer-supply = "avdd_pll_x";
       };
       c8 {
        regulator-consumer-supply = "avdd_pll_cg";
       };
      };
     };

     ldo2 {
      regulator-name = "vdd-1v2";
      regulator-min-microvolt = <1200000>;
      regulator-max-microvolt = <1200000>;

      consumers {
       c0 {
        regulator-consumer-supply = "vdd_1v2_cam";
       };
       c1 {
        regulator-consumer-supply = "vdig";
        regulator-consumer-device = "2-0010";
       };
       c2 {
        regulator-consumer-supply = "vdig";
        regulator-consumer-device = "2-0036";
       };
      };
     };

     ldo3 {
      regulator-name = "vdd-touch";
      regulator-min-microvolt = <3100000>;
      regulator-max-microvolt = <3100000>;

      consumers {
       c0 {
        regulator-consumer-supply = "avdd";
        regulator-consumer-device = "spi0.0";
       };
      };
     };

     ldo4 {
      regulator-name = "avdd-hsic";

      consumers {
       c0 {
        regulator-consumer-supply = "vddio_hsic";
        regulator-consumer-device = "tegra-ehci.1";
       };
       c1 {
        regulator-consumer-supply = "vddio_hsic";
        regulator-consumer-device = "tegra-ehci.2";
       };
       c2 {
        regulator-consumer-supply = "vddio_hsic";
        regulator-consumer-device = "tegra-xhci";
       };
       c3 {
        regulator-consumer-supply = "avdd_dsi_csi";
        regulator-consumer-device = "tegradc.0";
       };
       c4 {
        regulator-consumer-supply = "avdd_dsi_csi";
        regulator-consumer-device = "tegradc.1";
       };
       c5 {
        regulator-consumer-supply = "avdd_dsi_csi";
        regulator-consumer-device = "vi.0";
       };
       c6 {
        regulator-consumer-supply = "avdd_dsi_csi";
        regulator-consumer-device = "vi.1";
       };
       c7 {
        regulator-consumer-supply = "pwrdet_mipi";
       };
       c8 {
        regulator-consumer-supply = "avdd_hsic_com";
       };
       c9 {
        regulator-consumer-supply = "avdd_hsic_mdm";
       };
       c10 {
        regulator-consumer-supply = "vdd_lcd_bl";
       };
      };

     };

     ldo5_reg: ldo5 {
      regulator-name = "vdd-2v7";
      regulator-min-microvolt = <2700000>;
      regulator-max-microvolt = <2700000>;

      consumers {
       c0 {
        regulator-consumer-supply = "vdd_2v7_hv";
       };
       c1 {
        regulator-consumer-supply = "avdd_cam1_cam";
       };
       c2 {
        regulator-consumer-supply = "avdd_cam2_cam";
       };
       c3 {
        regulator-consumer-supply = "avdd_cam3_cam";
       };
       c4 {
        regulator-consumer-supply = "vana";
        regulator-consumer-device = "2-0010";
       };
       c5 {
        regulator-consumer-supply = "avdd_ov5693";
        regulator-consumer-device = "2-0010";
       };
      };

     };

     ldo6 {
      regulator-name = "vdd-cam-af";
      regulator-min-microvolt = <1800000>;
      regulator-max-microvolt = <1800000>;
      regulator-always-on;
      regulator-boot-on;

      consumers {
       c0 {
        regulator-consumer-supply = "vdd_cam1_1v8_cam";
       };
       c1 {
        regulator-consumer-supply = "vdd_cam2_1v8_cam";
       };
       c2 {
        regulator-consumer-supply = "vif";
        regulator-consumer-device = "2-0010";
       };
       c3 {
        regulator-consumer-supply = "vif";
        regulator-consumer-device = "2-0036";
       };
       c4 {
        regulator-consumer-supply = "vdd_i2c";
        regulator-consumer-device = "2-000c";
       };
       c5 {
        regulator-consumer-supply = "vi2c";
        regulator-consumer-device = "2-0030";
       };
       c6 {
        regulator-consumer-supply = "vif2";
        regulator-consumer-device = "2-0021";
       };
       c7 {
        regulator-consumer-supply = "dovdd";
        regulator-consumer-device = "2-0010";
       };
       c8 {
        regulator-consumer-supply = "vdd";
        regulator-consumer-device = "2-004a";
       };
       c9 {
        regulator-consumer-supply = "vif";
        regulator-consumer-device = "2-0048";
       };
      };
     };

     ldo7 {
      regulator-name = "avdd-cam-af";
      regulator-min-microvolt = <2700000>;
      regulator-max-microvolt = <2700000>;

      consumers {
       c0 {
        regulator-consumer-supply = "avdd_af1_cam";
       };
       c1 {
        regulator-consumer-supply = "imx135_reg1";
       };
       c2 {
        regulator-consumer-supply = "vdd";
        regulator-consumer-device = "2-000c";
       };
       c3 {
        regulator-consumer-supply = "vin";
        regulator-consumer-device = "2-0030";
       };
       c4 {
        regulator-consumer-supply = "vana";
        regulator-consumer-device = "2-0036";
       };
       c5 {
        regulator-consumer-supply = "vana";
        regulator-consumer-device = "2-0021";
       };
       c6 {
        regulator-consumer-supply = "vdd_af1";
        regulator-consumer-device = "2-0010";
       };
       c7 {
        regulator-consumer-supply = "vin";
        regulator-consumer-device = "2-004a";
       };
       c8 {
        regulator-consumer-supply = "vana";
        regulator-consumer-device = "2-0048";
       };
      };
     };

     ldo8 {
      regulator-name = "vdd-rtc";
      regulator-min-microvolt = <800000>;
      regulator-max-microvolt = <800000>;
      regulator-always-on;
      regulator-boot-on;
      ti,enable-ldo8-tracking;

      consumers {
       c0 {
        regulator-consumer-supply = "vdd_rtc";
       };
      };
     };

     ldo9 {
      regulator-name = "vddio-sdmmc2";
      regulator-min-microvolt = <1800000>;
      regulator-max-microvolt = <3300000>;

      consumers {
       c0 {
        regulator-consumer-supply = "vddio_sdmmc";
        regulator-consumer-device = "sdhci-tegra.2";
       };
       c1 {
        regulator-consumer-supply = "pwrdet_sdmmc3";
       };
      };
     };

     palmas_ldoln: ldoln {
      regulator-name = "vdd-cam-1v05";
      regulator-min-microvolt = <1050000>;
      regulator-max-microvolt = <1050000>;

      consumers {
       c0 {
        regulator-consumer-supply = "vdd_cam_1v1_cam";
       };
       c1 {
        regulator-consumer-supply = "imx135_reg2";
       };
       c2 {
        regulator-consumer-supply = "vdig_lv";
        regulator-consumer-device = "2-0010";
       };
       c3 {
        regulator-consumer-supply = "dvdd";
        regulator-consumer-device = "2-0010";
       };
      };
     };

     ldousb_reg: ldousb {
      regulator-name = "vpp-fuse";
      regulator-min-microvolt = <1800000>;
      regulator-max-microvolt = <1800000>;
      regulator-always-on;
      regulator-boot-on;
     };

     palmas_ti913_regen1: regen1 {
      regulator-name = "switch-1v8";
      regulator-min-microvolt = <2800000>;
      regulator-max-microvolt = <3300000>;
      regulator-always-on;
      regulator-boot-on;

      consumers {
       c0 {
        regulator-consumer-supply = "micvdd";
        regulator-consumer-device = "tegra-snd-rt5645.0";
       };
       c1 {
        regulator-consumer-supply = "vddio_hv";
        regulator-consumer-device = "tegradc.1";
       };
       c2 {
        regulator-consumer-supply = "pwrdet_hv";
       };
       c3 {
        regulator-consumer-supply = "avdd_usb";
        regulator-consumer-device = "tegra-udc.0";
       };
       c4 {
        regulator-consumer-supply = "avdd_usb";
        regulator-consumer-device = "tegra-ehci.0";
       };
       c5 {
        regulator-consumer-supply = "avdd_usb";
        regulator-consumer-device = "tegra-ehci.1";
       };
       c6 {
        regulator-consumer-supply = "avdd_usb";
        regulator-consumer-device = "tegra-ehci.2";
       };
       c7 {
        regulator-consumer-supply = "hvdd_usb";
        regulator-consumer-device = "tegra-xhci";
       };
       c8 {
        regulator-consumer-supply = "vddio_sd_slot";
        regulator-consumer-device = "sdhci-tegra.3";
       };
       c9 {
        regulator-consumer-supply = "hvdd_pex";
        regulator-consumer-device = "tegra-pcie";
       };
       c10 {
        regulator-consumer-supply = "hvdd_pex_pll_e";
        regulator-consumer-device = "tegra-pcie";
       };
       c11 {
        regulator-consumer-supply = "vddio_pex_ctl";
        regulator-consumer-device = "tegra-pcie";
       };
       c12 {
        regulator-consumer-supply = "pwrdet_pex_ctl";
       };
       c13 {
        regulator-consumer-supply = "vdd";
        regulator-consumer-device = "0-0069";
       };
       c14 {
        regulator-consumer-supply = "vdd";
        regulator-consumer-device = "0-0048";
       };
       c15 {
        regulator-consumer-supply = "vdd";
        regulator-consumer-device = "stm8t143.2";
       };
       c16 {
        regulator-consumer-supply = "vdd";
        regulator-consumer-device = "0-000c";
       };
       c17 {
        regulator-consumer-supply = "vdd";
        regulator-consumer-device = "0-0077";
       };
       c18 {
        regulator-consumer-supply = "hvdd_sata";
        regulator-consumer-device = "tegra-sata.0";
       };
       c19 {
        regulator-consumer-supply = "vdd";
        regulator-consumer-device = "1-004c";
       };
       c20 {
        regulator-consumer-supply = "vdd";
        regulator-consumer-device = "1-004d";
       };
       c21 {
        regulator-consumer-supply = "vcc";
        regulator-consumer-device = "1-0071";
       };
      };
     };
    };
   };
  };
 };


 efuse@7000f800 {
  vpp_fuse-supply = <&ldousb_reg>;
 };
};
# 5 "arch/arm/boot/dts/tegra124-ardbeg-e1792-1100-a00-00.dts" 2
# 1 "arch/arm/boot/dts/tegra124-platforms/tegra124-ardbeg-fixed-e1735-1000-a00.dtsi" 1


/ {
 regulators {
  compatible = "simple-bus";
  device_type = "fixed-regulators";
  #address-cells = <1>;
  #size-cells = <0>;

  battery_ardbeg: regulator@0 {
   compatible = "regulator-fixed";
   reg = <0>;
   regulator-name = "vdd_ac_bat";
   regulator-min-microvolt = <5000000>;
   regulator-max-microvolt = <5000000>;
   regulator-always-on;

   consumers {
    c0 {
     regulator-consumer-supply = "vdd_sys_bl";
    };
   };
  };

  vdd_hdmi_5v0: regulator@1 {
   compatible = "regulator-fixed-sync";
   reg = <1>;
   regulator-name = "vdd-hdmi-5v0";
   regulator-min-microvolt = <5000000>;
   regulator-max-microvolt = <5000000>;
   gpio = <&gpio ((10 * 8) + 6) 0>;
   enable-active-high;

   consumers {
    c0 {
     regulator-consumer-supply = "vdd_hdmi_5v0";
     regulator-consumer-device = "tegradc.1";
    };
   };
  };

  usb0_vbus: regulator@2 {
   compatible = "regulator-fixed-sync";
   reg = <2>;
   regulator-name = "usb0-vbus";
   regulator-min-microvolt = <5000000>;
   regulator-max-microvolt = <5000000>;
   gpio = <&gpio ((13 * 8) + 4) 0>;
   enable-active-high;
   gpio-open-drain;

   consumers {
    c0 {
     regulator-consumer-supply = "usb_vbus";
     regulator-consumer-device = "tegra-ehci.0";
    };
    c1 {
     regulator-consumer-supply = "usb_vbus";
     regulator-consumer-device = "tegra-otg";
    };
    c2 {
     regulator-consumer-supply = "usb_vbus0";
     regulator-consumer-device = "tegra-xhci";
    };
   };
  };

  usb1_vbus: regulator@3 {
   compatible = "regulator-fixed-sync";
   reg = <3>;
   regulator-name = "usb1_vbus";
   regulator-min-microvolt = <5000000>;
   regulator-max-microvolt = <5000000>;
   gpio = <&gpio ((13 * 8) + 5) 0>;
   enable-active-high;
   gpio-open-drain;

   consumers {
    c0 {
     regulator-consumer-supply = "usb_vbus";
     regulator-consumer-device = "tegra-ehci.1";
    };
    c1 {
     regulator-consumer-supply = "usb_vbus1";
     regulator-consumer-device = "tegra-xhci";
    };
   };
  };

  usb2_vbus: regulator@4 {
   compatible = "regulator-fixed-sync";
   reg = <4>;
   regulator-name = "usb2_vbus";
   regulator-min-microvolt = <5000000>;
   regulator-max-microvolt = <5000000>;
   gpio = <&gpio ((31 * 8) + 1) 0>;
   enable-active-high;
   gpio-open-drain;

   consumers {
    c0 {
     regulator-consumer-supply = "usb_vbus";
     regulator-consumer-device = "tegra-ehci.2";
    };
    c1 {
     regulator-consumer-supply = "usb_vbus2";
     regulator-consumer-device = "tegra-xhci";
    };
   };
  };

  lcd_bl_en: regulator@5 {
   compatible = "regulator-fixed-sync";
   reg = <5>;
   regulator-name = "lcd_bl_en";
   regulator-min-microvolt = <5000000>;
   regulator-max-microvolt = <5000000>;
   gpio = <&gpio ((7 * 8) + 2) 0>;
   enable-active-high;

   consumers {
    c0 {
     regulator-consumer-supply = "vdd_lcd_bl_en";
    };
   };
  };

  dcdc_1v8: regulator@6 {
   compatible = "regulator-fixed";
   reg = <6>;
   regulator-name = "dcdc-1v8";
   regulator-min-microvolt = <1800000>;
   regulator-max-microvolt = <1800000>;

   consumers {
    c0 {
     regulator-consumer-supply = "avdd_lvds0_pll";
    };
    c1 {
     regulator-consumer-supply = "vdd_ds_1v8";
    };
   };
  };

  vdd_sys_5v0: regulator@7 {
   compatible = "regulator-fixed";
   reg = <7>;
   regulator-name = "vdd-sys-5v0";
   regulator-min-microvolt = <5000000>;
   regulator-max-microvolt = <5000000>;

   consumers {
    c0 {
     regulator-consumer-supply = "vdd_spk_5v0";
    };
    c1 {
     regulator-consumer-supply = "spkvdd";
     regulator-consumer-device = "tegra-snd-rt5639.0";
    };
    c2 {
     regulator-consumer-supply = "spkvdd";
     regulator-consumer-device = "tegra-snd-rt5645.0";
    };
   };
  };

  vdd_sd: regulator@8 {
   compatible = "regulator-fixed-sync";
   reg = <8>;
   regulator-name = "vdd-sd";
   regulator-min-microvolt = <3300000>;
   regulator-max-microvolt = <3300000>;
   gpio = <&gpio ((17 * 8) + 0) 0>;
   enable-active-high;

   consumers {
    c0 {
     regulator-consumer-supply = "vddio_sd_slot";
     regulator-consumer-device = "sdhci-tegra.2";
    };
   };
  };

  ti913_gpio2: regulator@9 {
   compatible = "regulator-fixed-sync";
   reg = <9>;
   regulator-name = "ti913-gpio2";
   regulator-min-microvolt = <3300000>;
   regulator-max-microvolt = <3300000>;
   regulator-always-on;
   regulator-boot-on;
   gpio = <&palmas_gpio 2 0>;
   enable-active-high;

   consumers {
    c0 {
     regulator-consumer-supply = "vdd_wwan_mdm";
    };
   };
  };

  ti913_gpio3: regulator@10 {
   compatible = "regulator-fixed-sync";
   reg = <10>;
   regulator-name = "ti913_gpio3";
   regulator-min-microvolt = <3300000>;
   regulator-max-microvolt = <3300000>;
   gpio = <&palmas_gpio 3 0>;
   enable-active-high;

   consumers {
    c0 {
     regulator-consumer-supply = "avdd_lcd";
    };
   };
  };

  ti913_gpio4: regulator@11 {
   compatible = "regulator-fixed-sync";
   reg = <11>;
   regulator-name = "ti913-gpio4";
   regulator-min-microvolt = <1200000>;
   regulator-max-microvolt = <1200000>;
   gpio = <&palmas_gpio 4 0>;
   enable-active-high;

   consumers {
    c0 {
     regulator-consumer-supply = "vdd_lcd_1v2_s";
    };
   };
  };

  ti913_gpio6: regulator@12 {
   compatible = "regulator-fixed-sync";
   reg = <12>;
   regulator-name = "ti913-gpio6";
   regulator-min-microvolt = <1200000>;
   regulator-max-microvolt = <1200000>;
   gpio = <&palmas_gpio 6 0>;
   enable-active-high;

   consumers {
    c0 {
     regulator-consumer-supply = "ldoen";
     regulator-consumer-device = "tegra-snd-rt5639.0";
    };
   };
  };

  ti913_gpio7: regulator@13 {
   compatible = "regulator-fixed-sync";
   reg = <13>;
   regulator-name = "ti913-gpio7";
   regulator-min-microvolt = <1800000>;
   regulator-max-microvolt = <1800000>;
   gpio = <&palmas_gpio 7 0>;
   enable-active-high;

   consumers {
    c0 {
     regulator-consumer-supply = "dvdd_lcd";
    };
    c1 {
     regulator-consumer-supply = "vdd_lcd_1v8_s";
    };
   };
  };

  vdd_cpu_fixed: regulator@14 {
   compatible = "regulator-fixed";
   reg = <14>;
   regulator-name = "vdd-cpu-fixed";
   regulator-min-microvolt = <1000000>;
   regulator-max-microvolt = <1000000>;
   regulator-boot-on;

   consumers {
    c0 {
    regulator-consumer-supply = "vdd_cpu_fixed";
    };
   };
  };

  en_bat: regulator@15 {
   compatible = "regulator-fixed-sync";
   reg = <15>;
   regulator-name = "en-bat";
   regulator-min-microvolt = <1800000>;
   regulator-max-microvolt = <1800000>;
   regulator-always-on;
   regulator-boot-on;
   gpio = <&gpio ((10 * 8) + 5) 0>;
   enable-active-high;
  };
 };
};
# 6 "arch/arm/boot/dts/tegra124-ardbeg-e1792-1100-a00-00.dts" 2
# 1 "arch/arm/boot/dts/tegra124-platforms/tegra124-e1780-e1735-dfll.dtsi" 1


/ {
 dfll@70110000 {
  board-params = <&{/cpu_dfll_board_params}>;
  status = "okay";
  pwm_dfll: pwm-pmic-integration {
   compatible = "nvidia,tegra124-dfll-pwm";
   pwm-1wire-buffer;
   pwm-data-gpio = <&gpio ((23 * 8) + 0) 0>;
   pwm-buffer-ctrl-gpio = <&gpio ((18 * 8) + 5) 1>;
   #pwm-cells = <2>;
   pwm-regulator = <&cpu_pwm_reg>;
  };
 };

 cpu_dfll_board_params {
  sample-rate = <50000>;
  fixed-output-forcing;
  cf = <10>;
  ci = <0>;
  cg = <2>;
  droop-cut-value = <0xf>;
  droop-restore-ramp = <0x0>;
  scale-out-ramp = <0x0>;
 };

 pwm_regulators {
  compatible = "simple-bus";
  #address-cells = <1>;
  #size-cells = <0>;

  cpu_pwm_reg: pwm-regulator@0 {
   reg = <0>;
   compatible = "regulator-pwm";
   pwms = <&pwm_dfll 0 2500>;
   regulator-name = "vdd-cpu-pwm-reg";
   regulator-min-microvolt = <675000>;
   regulator-max-microvolt = <1275000>;
   regulator-init-microvolt = <1000000>;
   regulator-always-on;
   regulator-boot-on;
   regulator-n-voltages = <33>;
   voltage-time-sel = <80>;
   idle-gpio = <&gpio ((23 * 8) + 2) 0>;

   consumers {
    c1 {
     regulator-consumer-supply = "vdd_cpu";
    };
   };
  };
 };
};
# 7 "arch/arm/boot/dts/tegra124-ardbeg-e1792-1100-a00-00.dts" 2

/ {
 nvidia,boardids = "1792:1100:00;1735:1000:01";
 nvidia,dtsfilename = "arch/arm/boot/dts/tegra124-ardbeg-e1792-1100-a00-00.dts";
 nvidia,proc-boardid = "1792:1100:00";
 nvidia,pmu-boardid = "1735:1000:01";

 i2c@7000d000 {
  tps65913@58 {
   pmic {
    regulators {
     smps7 {
      regulator-min-microvolt = <1200000>;
      regulator-max-microvolt = <1200000>;
     };
    };
   };
  };
 };
};
